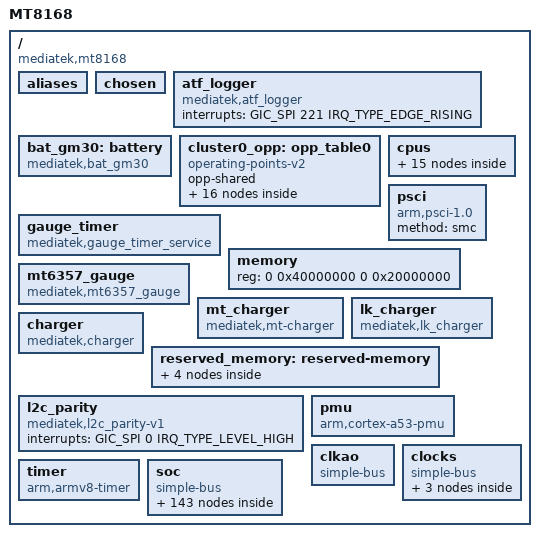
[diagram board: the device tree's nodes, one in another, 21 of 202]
/*
 * Mediatek's MT8168 SoC device tree source
 * Copyright (c) 2014-2015 MediaTek Inc.
 *
 * This program is free software; you can redistribute it and/or modify
 * it under the terms of the GNU General Public License version 2 as
 * published by the Free Software Foundation.
 *
 * This program is distributed in the hope that it will be useful,
 * MERCHANTABILITY or FITNESS FOR A PARTICULAR PURPOSE.  See the
 * GNU General Public License for more details.
 */

#include <dt-bindings/clock/mt8168-clk.h>
#include <dt-bindings/power/mt8168-power.h>
#include <dt-bindings/iio/mt635x-auxadc.h>
#include <dt-bindings/interrupt-controller/irq.h>
#include <dt-bindings/interrupt-controller/arm-gic.h>
#include <dt-bindings/reset/mt8168-resets.h>
#include <dt-bindings/memory/mt8168-larb-port.h>
#include <dt-bindings/phy/phy.h>
#include <dt-bindings/pinctrl/mt8168-pinfunc.h>
#include <dt-bindings/power/mt8168-power.h>
#include <dt-bindings/mfd/mt6357-irq.h>

/ {
	model = "MT8168";
	compatible = "mediatek,mt8168";
	interrupt-parent = <&sysirq>;
	#address-cells = <2>;
	#size-cells = <2>;

	aliases {
		ovl0 = &disp_ovl0;
		ovl_2l0 = &disp_ovl0_2l;
		rdma0 = &disp_rdma0;
		rdma1 = &disp_rdma1;
		wdma0 = &disp_wdma0;
		color0 = &disp_color0;
		ccorr0 = &disp_ccorr0;
		dsi0 = &dsi0;
		aal0 = &disp_aal0;
		gamma0 = &disp_gamma0;
		dither0 = &disp_dither0;
	};

	/* chosen */
	chosen: chosen {
		bootargs = "console=tty0 console=ttyS0,921600n1 earlycon=uart8250,mmio32,0x11002000 vmalloc=496M androidboot.hardware=mt8168 firmware_class.path=/vendor/firmware loop.max_part=7";
	};
	/* ATF logger SW IRQ number 253 = 32 + 221 */
	atf_logger {
		compatible = "mediatek,atf_logger";
		interrupts = <GIC_SPI 221 IRQ_TYPE_EDGE_RISING>;
	};

	bat_gm30: battery {
		compatible = "mediatek,bat_gm30";
	};

	cluster0_opp: opp_table0 {
		compatible = "operating-points-v2";
		opp-shared;
		opp-850000000 {
			opp-hz = /bits/ 64 <850000000>;
			opp-microvolt = <650000>;
		};
		opp-918000000 {
			opp-hz = /bits/ 64 <918000000>;
			opp-microvolt = <668750>;
		};
		opp-987000000 {
			opp-hz = /bits/ 64 <987000000>;
			opp-microvolt = <687500>;
		};
		opp-1056000000 {
			opp-hz = /bits/ 64 <1056000000>;
			opp-microvolt = <706250>;
		};
		opp-1125000000 {
			opp-hz = /bits/ 64 <1125000000>;
			opp-microvolt = <725000>;
		};
		opp-1216000000 {
			opp-hz = /bits/ 64 <1216000000>;
			opp-microvolt = <750000>;
		};
		opp-1308000000 {
			opp-hz = /bits/ 64 <1308000000>;
			opp-microvolt = <775000>;
		};
		opp-1400000000 {
			opp-hz = /bits/ 64 <1400000000>;
			opp-microvolt = <800000>;
		};
		opp-1466000000 {
			opp-hz = /bits/ 64 <1466000000>;
			opp-microvolt = <825000>;
		};
		opp-1533000000 {
			opp-hz = /bits/ 64 <1533000000>;
			opp-microvolt = <850000>;
		};
		opp-1633000000 {
			opp-hz = /bits/ 64 <1633000000>;
			opp-microvolt = <887500>;
		};
		opp-1700000000 {
			opp-hz = /bits/ 64 <1700000000>;
			opp-microvolt = <912500>;
		};
		opp-1767000000 {
			opp-hz = /bits/ 64 <1767000000>;
			opp-microvolt = <937500>;
		};
		opp-1834000000 {
			opp-hz = /bits/ 64 <1834000000>;
			opp-microvolt = <962500>;
		};
		opp-1917000000 {
			opp-hz = /bits/ 64 <1917000000>;
			opp-microvolt = <993750>;
		};
		opp-2001000000 {
			opp-hz = /bits/ 64 <2001000000>;
			opp-microvolt = <1025000>;
		};
	};

	cpus: cpus {
		#address-cells = <1>;
		#size-cells = <0>;

		cpu-map {
			cluster0: cluster0 {
				core0 {
					cpu = <&cpu0>;
				};
				core1 {
					cpu = <&cpu1>;
				};
				core2 {
					cpu = <&cpu2>;
				};
				core3 {
					cpu = <&cpu3>;
				};
			};
		};

		cpu0: cpu@0 {
			device_type = "cpu";
			compatible = "arm,cortex-a53";
			reg = <0x0>;
			clock-frequency = <1600000000>;
			enable-method = "psci";
			cpu-idle-states = <&MCDI_CPU &MCDI_CLUSTER &SODI
					   &DPIDLE>;
			clocks = <&mcusys CLK_MCU_BUS_SEL>,
				 <&apmixedsys CLK_APMIXED_MAINPLL>,
				 <&apmixedsys CLK_APMIXED_ARMPLL>;
			clock-names = "cpu", "intermediate", "armpll";
			operating-points-v2 = <&cluster0_opp>;
		};

		cpu1: cpu@1 {
			device_type = "cpu";
			compatible = "arm,cortex-a53";
			reg = <0x1>;
			clock-frequency = <1600000000>;
			enable-method = "psci";
			cpu-idle-states = <&MCDI_CPU &MCDI_CLUSTER &SODI
					   &DPIDLE>;
			clocks = <&mcusys CLK_MCU_BUS_SEL>,
				 <&apmixedsys CLK_APMIXED_MAINPLL>,
				 <&apmixedsys CLK_APMIXED_ARMPLL>;
			clock-names = "cpu", "intermediate", "armpll";
			operating-points-v2 = <&cluster0_opp>;
		};

		cpu2: cpu@2 {
			device_type = "cpu";
			compatible = "arm,cortex-a53";
			reg = <0x2>;
			clock-frequency = <1600000000>;
			enable-method = "psci";
			cpu-idle-states = <&MCDI_CPU &MCDI_CLUSTER &SODI
					   &DPIDLE>;
			clocks = <&mcusys CLK_MCU_BUS_SEL>,
				 <&apmixedsys CLK_APMIXED_MAINPLL>,
				 <&apmixedsys CLK_APMIXED_ARMPLL>;
			clock-names = "cpu", "intermediate", "armpll";
			operating-points-v2 = <&cluster0_opp>;
		};

		cpu3: cpu@3 {
			device_type = "cpu";
			compatible = "arm,cortex-a53";
			reg = <0x3>;
			clock-frequency = <1600000000>;
			enable-method = "psci";
			cpu-idle-states = <&MCDI_CPU &MCDI_CLUSTER &SODI
					   &DPIDLE>;
			clocks = <&mcusys CLK_MCU_BUS_SEL>,
				 <&apmixedsys CLK_APMIXED_MAINPLL>,
				 <&apmixedsys CLK_APMIXED_ARMPLL>;
			clock-names = "cpu", "intermediate", "armpll";
			operating-points-v2 = <&cluster0_opp>;
		};

		idle-states {
			entry-method = "psci";

			MCDI_CPU: mcdi-cpu {
				compatible = "arm,idle-state";
				local-timer-stop;
				arm,psci-suspend-param = <0x00010001>;
				entry-latency-us = <300>;
				exit-latency-us = <200>;
				min-residency-us = <1000>;
			};

			MCDI_CLUSTER: mcdi-cluster {
				compatible = "arm,idle-state";
				local-timer-stop;
				arm,psci-suspend-param = <0x01010001>;
				entry-latency-us = <350>;
				exit-latency-us = <250>;
				min-residency-us = <1200>;
			};

			SODI: sodi {
				compatible = "arm,idle-state";
				local-timer-stop;
				arm,psci-suspend-param = <0x01010002>;
				entry-latency-us = <300>;
				exit-latency-us = <850>;
				min-residency-us = <2300>;
			};

			DPIDLE: dpidle {
				compatible = "arm,idle-state";
				local-timer-stop;
				arm,psci-suspend-param = <0x01010004>;
				entry-latency-us = <350>;
				exit-latency-us = <1050>;
				min-residency-us = <2800>;
			};
		};
	};

	gauge_timer {
		compatible = "mediatek,gauge_timer_service";
	};

	psci {
		compatible      = "arm,psci-1.0";
		method          = "smc";
	};

	memory {
		device_type = "memory";
		reg = <0 0x40000000 0 0x20000000>;
	};

	mt6357_gauge {
		compatible = "mediatek,mt6357_gauge";
		gauge_name = "gauge";
		alias_name = "MT6357";
	};

	mt_charger: mt_charger {
		compatible = "mediatek,mt-charger";
	};

	lk_charger: lk_charger {
		compatible = "mediatek,lk_charger";
		enable_anime;
		enable_pe_plus;
		power_path_support;
		max_charger_voltage = <6500000>;
		fast_charge_voltage = <3000000>;

		/* charging current */
		usb_charger_current = <500000>;
		ac_charger_current = <2050000>;
		ac_charger_input_current = <3200000>;
		non_std_ac_charger_current = <500000>;
		charging_host_charger_current = <1500000>;
		ta_ac_charger_current = <3000000>;
		pd_charger_current = <500000>;

		/* battery temperature protection */
		temp_t4_threshold = <50>;
		temp_t3_threshold = <45>;
		temp_t1_threshold = <0>;
	};

	charger: charger {
		compatible = "mediatek,charger";
		algorithm_name = "SwitchCharging";
		/* enable_sw_jeita; */
		enable_pe_plus;
		enable_type_c;
		power_path_support;

		/* common */
		battery_cv = <4200000>;
		max_charger_voltage = <6500000>;
		min_charger_voltage = <4600000>;

		/* charging current */
		usb_charger_current_suspend = <0>;
		usb_charger_current_unconfigured = <70000>;
		usb_charger_current_configured = <500000>;
		usb_charger_current = <500000>;
		ac_charger_current = <2050000>;
		ac_charger_input_current = <3200000>;
		non_std_ac_charger_current = <500000>;
		charging_host_charger_current = <1500000>;
		apple_1_0a_charger_current = <650000>;
		apple_2_1a_charger_current = <800000>;
		ta_ac_charger_current = <3000000>;

		/* sw jeita */
		jeita_temp_above_t4_cv = <4240000>;
		jeita_temp_t3_to_t4_cv = <4240000>;
		jeita_temp_t2_to_t3_cv = <4340000>;
		jeita_temp_t1_to_t2_cv = <4240000>;
		jeita_temp_t0_to_t1_cv = <4040000>;
		jeita_temp_below_t0_cv = <4040000>;
		temp_t4_thres = <50>;
		temp_t4_thres_minus_x_degree = <47>;
		temp_t3_thres = <45>;
		temp_t3_thres_minus_x_degree = <39>;
		temp_t2_thres = <10>;
		temp_t2_thres_plus_x_degree = <16>;
		temp_t1_thres = <0>;
		temp_t1_thres_plus_x_degree = <6>;
		temp_t0_thres = <0>;
		temp_t0_thres_plus_x_degree = <0>;
		temp_neg_10_thres = <0>;

		/* battery temperature protection */
		enable_min_charge_temp;
		min_charge_temp = <0>;
		min_charge_temp_plus_x_degree = <6>;
		max_charge_temp = <50>;
		max_charge_temp_minus_x_degree = <47>;

		/* PE */
		ta_12v_support;
		ta_9v_support;
		pe_ichg_level_threshold = <1000000>; /* uA */
		ta_ac_12v_input_current = <3200000>;
		ta_ac_9v_input_current = <3200000>;
		ta_ac_7v_input_current = <3200000>;

		/* cable measurement impedance */
		cable_imp_threshold = <699>;
		vbat_cable_imp_threshold = <3900000>; /* uV */

		/* bif */
		bif_threshold1 = <4250000>;
		bif_threshold2 = <4300000>;
		bif_cv_under_threshold2 = <4450000>;
	};

	reserved_memory: reserved-memory {
		#address-cells = <2>;
		#size-cells = <2>;
		ranges;

		adsp_reserved: adsp-reserved-memory@50000000 {
			compatible = "mediatek,adsp-reserved-memory";
			no-map;
			reg = <0 0x50000000 0 0x1800000>;
		};

		atf_reserved_memory: atf-reserved-memory {
			compatible = "mediatek,mt8168-atf-reserved-memory";
			no-map;
			reg = <0 0x54600000 0 0x30000>;
		};

		consys-reserve-memory {
			compatible = "mediatek,consys-reserve-memory";
			no-map;
			size = <0 0x400000>;
			alignment = <0 0x1000000>;
			alloc-ranges = <0 0x40000000 0 0x80000000>;
		};

		wifi-reserve-memory {
			compatible = "mediatek,wifi-reserve-memory";
			no-map;
			size = <0 0x300000>;
			alignment = <0 0x1000000>;
			alloc-ranges = <0 0x40000000 0 0x80000000>;
		};
	};

	l2c_parity {
		compatible = "mediatek,l2c_parity-v1";
		interrupts = <GIC_SPI 0 IRQ_TYPE_LEVEL_HIGH>;
	};

	pmu {
		compatible = "arm,cortex-a53-pmu",
			     "arm,cortex-a7-pmu";
		interrupt-parent = <&gic>;
		interrupts = <GIC_PPI 7 IRQ_TYPE_LEVEL_LOW>;
	};

	clkao: clkao {
		compatible = "simple-bus";
	};

	clocks {
		#address-cells = <2>;
		#size-cells = <2>;
		compatible = "simple-bus";
		ranges;

		clk26m: clk26m {
			compatible = "fixed-clock";
			#clock-cells = <0>;
			clock-frequency = <26000000>;
		};

		clk32k: clk32k {
			compatible = "fixed-clock";
			#clock-cells = <0>;
			clock-frequency = <32000>;
		};

		uart_clk: dummy26m {
			compatible = "fixed-clock";
			clock-frequency = <26000000>;
			#clock-cells = <0>;
		};
	};

	timer: timer {
		compatible = "arm,armv8-timer";
		interrupt-parent = <&gic>;
		interrupts = <GIC_PPI 13
			     (GIC_CPU_MASK_SIMPLE(4) | IRQ_TYPE_LEVEL_LOW)>,
			     <GIC_PPI 14
			     (GIC_CPU_MASK_SIMPLE(4) | IRQ_TYPE_LEVEL_LOW)>,
			     <GIC_PPI 11
			     (GIC_CPU_MASK_SIMPLE(4) | IRQ_TYPE_LEVEL_LOW)>,
			     <GIC_PPI 10
			     (GIC_CPU_MASK_SIMPLE(4) | IRQ_TYPE_LEVEL_LOW)>;
		clock-frequency = <13000000>;
	};

	soc {
		#address-cells = <2>;
		#size-cells = <2>;
		compatible = "simple-bus";
		ranges;

		chipid: chipid@08000000 {
			compatible = "mediatek,chipid";
			reg = <0 0x08000000 0 0x0004>,
			      <0 0x08000004 0 0x0004>,
			      <0 0x08000008 0 0x0004>,
			      <0 0x0800000c 0 0x0004>;
		};

		gic: interrupt-controller@c000000 {
			compatible = "arm,gic-v3";
			interrupt-controller;
			#interrupt-cells = <3>;
			#address-cells = <2>;
			#size-cells = <2>;
			#redistributor-regions = <1>;
			interrupt-parent = <&gic>;
			reg = <0 0xc000000 0 0x80000>,
			      <0 0xc080000 0 0x80000>;
			interrupts = <GIC_PPI 9
				(GIC_CPU_MASK_SIMPLE(4) | IRQ_TYPE_LEVEL_HIGH)>;
		};

		topckgen: topckgen@10000000 {
			compatible = "mediatek,mt8168-topckgen", "syscon";
			reg = <0 0x10000000 0 0x1000>;
			#clock-cells = <1>;
		};

		infracfg: infracfg@10001000 {
			compatible = "mediatek,mt8168-infracfg", "syscon";
			reg = <0 0x10001000 0 0x1000>;
			#clock-cells = <1>;
		};

		syscfg_pctl_a: syscfg_pctl_a@10005000 {
			compatible = "mediatek,pctl-a-syscfg", "syscon";
			reg = <0 0x10005000 0 0x1000>;
		};

		scpsys: syscon@10006000 {
			compatible = "mediatek,mt8168-scpsys", "syscon";
			#power-domain-cells = <1>;
			reg = <0 0x10006000 0 0x1000>;
			clocks = <&topckgen CLK_TOP_AUD_INTBUS_SEL>,
				 <&infracfg CLK_IFR_AUDIO>,
				 <&infracfg CLK_IFR_AUD_26M_BK>,
				 <&topckgen CLK_TOP_MFG_SEL>,
				 <&topckgen CLK_TOP_MM_SEL>,
				 <&topckgen CLK_TOP_DSP_SEL>,
				 <&topckgen CLK_TOP_DSP_26M>,
				 <&mmsys CLK_MM_MM_SMI_COMMON>,
				 <&mmsys CLK_MM_MM_SMI_COMM0>,
				 <&mmsys CLK_MM_MM_SMI_COMM1>,
				 <&mmsys CLK_MM_MM_SMI_LARB0>,
				 <&camsys CLK_CAM_LARB2>,
				 <&camsys CLK_CAM_SENIF>,
				 <&camsys CLK_CAMSV0>,
				 <&camsys CLK_CAMSV1>,
				 <&camsys CLK_CAM_FDVT>,
				 <&camsys CLK_CAM_WPE>,
				 <&infracfg CLK_IFR_APU_AXI>,
				 <&apu CLK_APU_IPU_CK>,
				 <&apu CLK_APU_AXI>,
				 <&apu CLK_APU_JTAG>,
				 <&apu CLK_APU_IF_CK>,
				 <&apu CLK_APU_EDMA>,
				 <&apu CLK_APU_AHB>,
				 <&topckgen CLK_TOP_CONN_32K>,
				 <&topckgen CLK_TOP_CONN_26M>;
			clock-names = "audio", "audio1", "audio2",
				      "mfg", "mm", "dsp", "dsp1",
				      "mm-0", "mm-1", "mm-2",
				      "mm-3", "cam-0","cam-1",
				      "cam-2", "cam-3", "cam-4",
				      "cam-5", "apu", "apu-1",
				      "apu-2", "apu-3", "apu-4",
				      "apu-5", "apu-6", "conn",
				      "conn1";
			infracfg = <&infracfg>;
			smi_comm = <&smi_common>;
			infracfg_nao = <&infracfg_nao>;
			conn-supply = <&mt_pmic_vcn28_ldo_reg>;
		};

		toprgu: toprgu@10007000 {
			compatible = "mediatek,mt8168-rgu",
				     "mediatek,mt6589-wdt";
			reg = <0 0x10007000 0 0x1000>;
			interrupts = <GIC_SPI 83 IRQ_TYPE_EDGE_FALLING>;
			#reset-cells = <1>;
		};

		gpt: apxgpt@10008000 {
			compatible = "mediatek,mt8168-timer",
				     "mediatek,mt6577-timer";
			reg = <0 0x10008000 0 0x1000>;
			interrupts = <GIC_SPI 114 IRQ_TYPE_LEVEL_LOW>;
			clocks = <&topckgen CLK_TOP_SYS_26M_D2>;
			clock-names = "clk13m";
		};

		pio: pinctrl@1000b000 {
			compatible = "mediatek,mt8168-pinctrl";
			reg = <0 0x1000b000 0 0x1000>;
			mediatek,pctl-regmap = <&syscfg_pctl_a>;
			pins-are-numbered;
			gpio-controller;
			#gpio-cells = <2>;
			interrupt-controller;
			#interrupt-cells = <2>;
			interrupts = <GIC_SPI 115 IRQ_TYPE_LEVEL_HIGH>;
		};

		apmixedsys: syscon@1000c000 {
			compatible = "mediatek,mt8168-apmixedsys", "syscon";
			reg = <0 0x1000c000 0 0x1000>;
			#clock-cells = <1>;
		};

		fhctl: fhctl@1000ce00 {
			compatible = "mediatek,fhctl";
			reg = <0 0x1000ce00 0 0x200>;
		};

		pwrap: pwrap@1000d000 {
			compatible = "mediatek,mt8168-pwrap";
			reg = <0 0x1000d000 0 0x1000>;
			reg-names = "pwrap";
			interrupts = <GIC_SPI 123 IRQ_TYPE_LEVEL_HIGH>;
			clocks = <&infracfg CLK_IFR_PWRAP_SPI>,
				<&infracfg CLK_IFR_PMIC_AP>,
				<&infracfg CLK_IFR_PWRAP_SYS>,
				<&infracfg CLK_IFR_PWRAP_TMR>;
			clock-names = "spi", "wrap", "wrap_sys", "wrap_tmr";

			main_pmic: mt6357-pmic {
				interrupt-parent = <&pio>;
				interrupts = <145 IRQ_TYPE_LEVEL_HIGH>;
				status = "okay";
			};
		};

		pwraph: pwraphal@ {
			compatible = "mediatek,pwraph";
			mediatek,pwrap-regmap = <&pwrap>;
		};

		keypad: keypad@10010000 {
			compatible = "mediatek,kp";
			reg = <0 0x10010000 0 0x1000>;
			interrupts = <GIC_SPI 124 IRQ_TYPE_EDGE_FALLING>;
		};

		dvfsrc@10012000 {
			compatible = "mediatek,dvfsrc";
			reg = <0 0x10012000 0 0x1000>,
			      <0 0x00110780 0 0x80>,
			      <0 0x10006000 0 0x1000>;
			clocks = <&infracfg CLK_IFR_DVFSRC>;
			clock-names = "dvfsrc";
		};

		irrx: irrx@1001F000 {
			compatible = "mediatek,mt8168-irrx";
			reg = <0 0x1001F000 0 0x1000>;
			interrupts = <GIC_SPI 142 IRQ_TYPE_LEVEL_LOW>;
			clocks = <&infracfg CLK_IFR_IRRX_32K>,
				 <&infracfg CLK_IFR_IRRX_26M>;
			clock-names = "irrx_clock", "irrx_sw_clock";
			status = "disabled";
		};

		mcusys: mcusys@10200000 {
			compatible = "mediatek,mt8168-mcusys",
				     "mediatek,mt8168-mcucfg", "syscon";
			reg = <0 0x10200000 0 0x2000>;
			interrupts = <GIC_SPI 0 IRQ_TYPE_LEVEL_HIGH>;
			#clock-cells = <1>;
		};

		sysirq: intpol-controller@10200a80 {
			compatible = "mediatek,mt8168-sysirq",
				     "mediatek,mt6577-sysirq";
			interrupt-controller;
			#interrupt-cells = <3>;
			interrupt-parent = <&gic>;
			reg = <0 0x10200a80 0 0x20>;
		};

		dfd: dfd@10200b00 {
			compatible = "mediatek,dfd";
			reg = <0 0x10200b00 0 0x10000>;
			mediatek,enabled = <1>;
			mediatek,chain_length = <0x61a8>;
			mediatek,rg_dfd_timeout = <0xa0>;
		};

		sys_cirq: sys_cirq@10202000 {
			compatible = "mediatek,mt8168-sys_cirq",
				     "mediatek,mt6735-sys_cirq",
				     "mediatek,sys_cirq";
			reg = <0 0x10202000 0 0x1000>;
			interrupts = <GIC_SPI 218 IRQ_TYPE_LEVEL_LOW>;
			mediatek,cirq_num = <147>;
			mediatek,spi_start_offset = <72>;
		};

		systracker: systracker@10208000 {
			compatible = "mediatek,bus_dbg-v2";
			reg = <0 0x10208000 0 0x1000>,
			      <0 0x10001000 0 0x1000>;
			mediatek,bus_dbg_con_offset = <0x2fc>;
			interrupts = <GIC_SPI 85 IRQ_TYPE_LEVEL_LOW>;
		};

		rng: rng@1020f000 {
			compatible = "mediatek,mt8168-rng",
				     "mediatek,mt7623-rng";
			reg = <0 0x1020f000 0 0x100>;
			clocks = <&infracfg CLK_IFR_TRNG>;
			clock-names = "rng";
		};

		apdma: dma-controller@11000280 {
			compatible = "mediatek,mt8168-uart-dma",
				     "mediatek,mt6577-uart-dma";
			reg = <0 0x11000280 0 0x80>,
			      <0 0x11000300 0 0x80>,
			      <0 0x11000380 0 0x80>,
			      <0 0x11000400 0 0x80>;
			interrupts = <GIC_SPI 45 IRQ_TYPE_LEVEL_LOW>,
				     <GIC_SPI 46 IRQ_TYPE_LEVEL_LOW>,
				     <GIC_SPI 47 IRQ_TYPE_LEVEL_LOW>,
				     <GIC_SPI 48 IRQ_TYPE_LEVEL_LOW>;
			dma-requests = <4>;
			clocks = <&infracfg CLK_IFR_AP_DMA>;
			clock-names = "apdma";
			#dma-cells = <1>;
		};

		spi: spi@1100a000 {
			compatible = "mediatek,mt8168-spi";
			#address-cells = <1>;
			#size-cells = <0>;
			reg = <0 0x1100a000 0 0x100>;
			interrupts = <GIC_SPI 62 IRQ_TYPE_LEVEL_LOW>;
			clocks = <&topckgen CLK_TOP_UNIVPLL2_D4>,
				 <&topckgen CLK_TOP_SPI_SEL>,
				 <&infracfg CLK_IFR_SPI0>;
			clock-names = "parent-clk", "sel-clk", "spi-clk";
			status = "disabled";
		};

		svs: svs@1100b000 {
			compatible = "mediatek,mt8168-svs";
			reg = <0 0x1100b000 0 0x1000>;
			interrupts = <GIC_SPI 69 IRQ_TYPE_LEVEL_LOW>;
			clocks = <&infracfg CLK_IFR_THERM>;
			clock-names = "main_clk";
			nvmem-cells = <&svs_calibration>;
			nvmem-cell-names = "svs-calibration-data";

			svs_cpu_little: svs_cpu_little {
				compatible = "mediatek,mt8168-svs-cpu-little";
				operating-points-v2 = <&cluster0_opp>;
			};
		};

		iommu: m4u@10205000 {
			compatible = "mediatek,mt8168-m4u";
			reg = <0 0x10205000 0 0x1000>;
			mediatek,larbs = <&larb0 &larb1 &larb2 &larb3>;
			interrupts = <GIC_SPI 102 IRQ_TYPE_LEVEL_LOW>;
			#iommu-cells = <1>;
		};

		infracfg_nao: infracfg_nao@1020e000 {
			compatible = "syscon";
			reg = <0 0x1020e000 0 0x1000>;
		};

		emi: emi@10219000 {
			compatible = "mediatek,mt8168-emi";
			reg = <0 0x10219000 0 0x1000>,
			      <0 0x10226000 0 0x1000>,
			      <0 0x1022f000 0 0x1000>,
			      <0 0x10239000 0 0x1000>;
			interrupts = <GIC_SPI 88 IRQ_TYPE_LEVEL_LOW>;
		};

		dramc: dramc@1022c000 {
			compatible = "mediatek,dramc";
			reg = <0 0x1022c000 0 0x2000>, /* DRAMC AO CHA */
			      <0 0x10232000 0 0x2000>, /* DRAMC AO CHB */
			      <0 0x1022e000 0 0x1000>, /* DRAMC NAO CHA */
			      <0 0x10238000 0 0x1000>, /* DRAMC NAO CHB */
			      <0 0x10228000 0 0x2000>, /* DDRPHY AO CHA */
			      <0 0x10234000 0 0x2000>, /* DDRPHY AO CHB */
			      <0 0x10230000 0 0x1000>, /* DDRPHY NAO CHA */
			      <0 0x1023a000 0 0x1000>, /* DDRPHY NAO CHB */
			      <0 0x10017000 0 0x1000>, /* sys timer */
			      <0 0x10006000 0 0x1000>; /* SPM */
		};

		gce: gce@1023c000 {
			compatible = "mediatek,gce", "syscon";
			reg = <0 0x1023c000 0 0x4000>;
			mediatek,larb = <&larb0>;
			power-domains = <&scpsys MT8168_POWER_DOMAIN_DISP>;
			#clock-cells = <1>;
			interrupts = <GIC_SPI 98 IRQ_TYPE_LEVEL_LOW>,
				     <GIC_SPI 99 IRQ_TYPE_LEVEL_LOW>;
			g3d_config_base = <0x13000000 0 0xffff0000>;
			mmsys_config_base = <0x14000000 1 0xffff0000>;
			disp_dither_base = <0x14010000 2 0xffff0000>;
			mm_na_base = <0x14020000 3 0xffff0000>;
			vdec_base = <0x16000000 30 0xffff0000>;
			vdec1_base = <0x16020000 31 0xffff0000>;
			camsys_base = <0x15000000 22 0xffff0000>;
			infracfg_ao_base = <0x10000000 10 0xffff0000>;
			devapc_ao_mm_base = <0x10010000 11 0xffff0000>;
			mdp_rdma0_sof = <0>;
			mdp_ccorr0_sof = <1>;
			mdp_rsz0_sof = <2>;
			mdp_rsz1_sof = <3>;
			mdp_wrot1_sof = <4>;
			mdp_wrot0_sof = <5>;
			mdp_tdshp0_sof = <6>;
			disp_ovl0_sof = <7>;
			disp_2l_ovl0_sof = <8>;
			disp_rdma0_sof = <9>;
			disp_rdma1_sof = <10>;
			disp_wdma0_sof = <11>;
			disp_color0_sof = <12>;
			disp_ccorr0_sof = <13>;
			disp_aal0_sof = <14>;
			disp_gamma0_sof = <15>;
			disp_dither0_sof = <16>;
			disp_dsi0_sof = <17>;
			img_dl_relay_sof = <18>;
			disp_rsz0_sof = <19>;
			disp_pwm0_sof = <20>;
			mdp_rdma1_sof = <21>;
			disp_dpi0_sof = <22>;
			mdp_rdma0_frame_done = <23>;
			mdp_ccorr0_frame_done = <24>;
			mdp_rsz0_frame_done = <25>;
			mdp_rsz1_frame_done = <26>;
			mdp_wrot0_write_frame_done = <27>;
			mdp_wrot1_write_frame_done = <28>;
			mdp_tdshp0_frame_done = <29>;
			disp_ovl0_frame_done = <30>;
			disp_2l_ovl0_frame_done = <31>;
			disp_rsz0_frame_done = <32>;
			disp_rdma0_frame_done = <33>;
			disp_rdma1_frame_done = <34>;
			disp_wdma0_frame_done = <35>;
			disp_color0_frame_done = <36>;
			disp_ccorr0_frame_done = <37>;
			disp_aal0_frame_done = <38>;
			disp_gamma0_frame_done = <39>;
			disp_dither0_frame_done = <40>;
			disp_dsi0_frame_done = <41>;
			mdp_rdma1_frame_done = <42>;
			disp_dpi0_frame_done = <43>;
			reserved1_frame_done = <44>;
			reserved0_frame_done = <45>;
			stream_done_0 = <130>;
			stream_done_1 = <131>;
			stream_done_2 = <132>;
			stream_done_3 = <133>;
			stream_done_4 = <134>;
			stream_done_5 = <135>;
			stream_done_6 = <136>;
			stream_done_7 = <137>;
			stream_done_8 = <138>;
			stream_done_9 = <139>;
			buf_underrun_event_0 = <140>;
			buf_underrun_event_1 = <141>;
			dsi0_te_pulse = <142>;
			dsi0_irq_event = <143>;
			dsi0_done_event = <144>;
			disp_wdma0_rst_done = <148>;
			mdp_wrot1_rst_done = <149>;
			mdp_wrot0_rst_done = <150>;
			mdp_rdma1_rst_done = <151>;
			mdp_rdma0_rst_done = <152>;
			disp_ovl0_frame_rst_done_pusle = <153>;
			isp_frame_done_p2_2 = <257>;
			isp_frame_done_p2_1 = <258>;
			isp_frame_done_p2_0 = <259>;
			isp_frame_done_p1_1 = <260>;
			isp_frame_done_p1_0 = <261>;
			camsv_0_pass1_done = <262>;
			camsv_1_pass1_done = <263>;
			seninf_cam0_fifo_full = <264>;
			seninf_cam1_fifo_full = <265>;
			seninf_cam2_fifo_full = <266>;
			seninf_cam3_fifo_full = <267>;
			seninf_cam4_fifo_full = <268>;
			seninf_cam5_fifo_full = <269>;
			seninf_cam6_fifo_full = <270>;
			seninf_cam7_fifo_full = <271>;
			fdvt_done = <272>;
			wpe_gce_frame_done = <273>;
			JPGENC_CMDQ_PAUSE_DONE = <289>;
			jpgenc_done = <290>;
			venc_cmdq_pause_done = <291>;
			venc_done = <292>;
			venc_mb_done = <293>;
			venc_128byte_cnt_done = <294>;
			out_event_0 = <898>;
			apu_gce_core0_event_0 = <321>;
			apu_gce_core0_event_1 = <322>;
			apu_gce_core0_event_2 = <323>;
			apu_gce_core0_event_3 = <324>;
			vdec_sof = <352>;
			vdec_frame_done_0 = <353>;
			vdec_frame_done_1 = <354>;
			vdec_frame_done_2 = <355>;
			vdec_frame_done_3 = <356>;
			vdec_frame_done_4 = <357>;
			vdec_frame_done_5 = <358>;
			vdec_frame_done_6 = <359>;
			vdec_event_0 = <360>;
			vdec_event_1 = <361>;
			vdec_event_2 = <362>;
			vdec_event_3 = <363>;
			vdec_event_4 = <364>;
			vdec_event_5 = <365>;
			vdec_event_6 = <366>;
			vdec_event_7 = <367>;
			max_prefetch_cnt = <1>;
			prefetch_size = <96>;
			sram_size_cpr_64 = <64>;
			mmsys_config = <&mmsys_config>;
			mdp_rdma0 = <&mdp_rdma0>;
			mdp_rdma1 = <&mdp_rdma1>;
			mdp_rsz0 = <&mdp_rsz0>;
			mdp_rsz1 = <&mdp_rsz1>;
			mdp_wrot0 = <&mdp_wrot0>;
			mdp_wrot1 = <&mdp_wrot1>;
			mdp_tdshp0 = <&mdp_tdshp0>;
			mdp_color0 = <&disp_color0>;
			mdp_ccorr0 = <&mdp_ccorr>;
			mm_mutex = <&disp_mutex0>;
			sram_share_cnt = <1>;
			sram_share_engine = <10>;
			sram_share_event = <710>;
			clocks = <&infracfg CLK_IFR_GCE>,
				 <&infracfg CLK_IFR_GCE_26M>;
			clock-names = "GCE", "GCE_TIMER";
			mediatek,mailbox-gce = <&gce_mbox>;
			mboxes = <&gce_mbox 0 0 4>,
				<&gce_mbox 1 0 4>,
				<&gce_mbox 2 0 5>,
				<&gce_mbox 3 0 4>,
				<&gce_mbox 4 0 4>,
				<&gce_mbox 5 0xffffffff 2>,
				<&gce_mbox 6 200 4>,
				<&gce_mbox 7 0xffffffff 2>,
				<&gce_mbox_svp 8 0 1>,
				<&gce_mbox_svp 9 0 4>,
				<&gce_mbox_svp 10 0 4>,
				<&gce_mbox 11 0 1>,
				<&gce_mbox 12 0 1>,
				<&gce_mbox 13 0 1>,
				<&gce_mbox 14 0 1>,
				<&gce_mbox 15 0xffffffff 1>;
		};

		gce_mbox: gce_mbox@1023c000 {
			compatible = "mediatek,mailbox-gce";
			reg = <0 0x1023c000 0 0x4000>;
			interrupts = <GIC_SPI 98 IRQ_TYPE_LEVEL_LOW>;
			#mbox-cells = <3>;
			#gce-event-cells = <1>;
			#gce-subsys-cells = <2>;
			clocks = <&infracfg CLK_IFR_GCE>,
				 <&infracfg CLK_IFR_GCE_26M>;
			clock-names = "gce", "GCE_TIMER";
		};

		gce_mbox_svp: gce_mbox_svp@1023c000 {
			compatible = "mediatek,mailbox-gce-svp";
			reg = <0 0x1023c000 0 0x4000>;
			interrupts = <GIC_SPI 98 IRQ_TYPE_LEVEL_LOW>;
			#mbox-cells = <3>;
			clocks = <&infracfg CLK_IFR_GCE>,
				 <&infracfg CLK_IFR_GCE_26M>;
			clock-names = "gce", "GCE_TIMER";
		};

		auxadc: adc@11001000 {
			compatible = "mediatek,mt8168-auxadc",
				     "mediatek,mt2701-auxadc";
			reg = <0 0x11001000 0 0x1000>;
			clocks = <&infracfg CLK_IFR_AUXADC>;
			clock-names = "main";
			#io-channel-cells = <1>;
			status = "disabled";
		};

		uart0: uart0@11002000 {
			compatible = "mediatek,mt8168-uart",
				     "mediatek,mt6577-uart";
			reg = <0 0x11002000 0 0x1000>;
			interrupts = <GIC_SPI 35 IRQ_TYPE_LEVEL_LOW>;
			clocks = <&clk26m>, <&infracfg CLK_IFR_UART0>;
			clock-names = "baud", "bus";
			dmas = <&apdma 0
				&apdma 1>;
			dma-names = "tx", "rx";
			status = "disabled";
		};

		uart1: uart1@11003000 {
			compatible = "mediatek,mt8168-uart",
				     "mediatek,mt6577-uart";
			reg = <0 0x11003000 0 0x1000>;
			interrupts = <GIC_SPI 36 IRQ_TYPE_LEVEL_LOW>;
			clocks = <&clk26m>, <&infracfg CLK_IFR_UART1>;
			clock-names = "baud", "bus";
			dmas = <&apdma 2
				&apdma 3>;
			dma-names = "tx", "rx";
			status = "disabled";
		};

		pwm: pwm@11006000 {
			compatible = "mediatek,mt8168-pwm";
			reg = <0 0x11006000 0 0x1000>;
			interrupts = <GIC_SPI 76 IRQ_TYPE_LEVEL_LOW>;
			clocks = <&infracfg CLK_IFR_PWM_HCLK>,
				 <&infracfg CLK_IFR_PWM>,
				 <&infracfg CLK_IFR_PWM1>,
				 <&infracfg CLK_IFR_PWM2>,
				 <&infracfg CLK_IFR_PWM3>;
			clock-names = "top", "main", "pwm1", "pwm2", "pwm3";
		};

		i2c0: i2c@11007000 {
			compatible = "mediatek,mt8168-i2c",
				     "mediatek,mt2712-i2c";
			reg = <0 0x11007000 0 0xa0>,
			      <0 0x11000080 0 0x80>;
			interrupts = <GIC_SPI 28 IRQ_TYPE_LEVEL_LOW>;
			clock-div = <1>;
			clocks = <&infracfg CLK_IFR_I2C0_AXI>,
				 <&infracfg CLK_IFR_AP_DMA>;
			clock-names = "main", "dma";
			#address-cells = <1>;
			#size-cells = <0>;
			status = "disabled";
		};

		i2c1: i2c@11008000 {
			compatible = "mediatek,mt8168-i2c",
				     "mediatek,mt2712-i2c";
			reg = <0 0x11008000 0 0xa0>,
			      <0 0x11000100 0 0x80>;
			interrupts = <GIC_SPI 29 IRQ_TYPE_LEVEL_LOW>;
			clock-div = <1>;
			clocks = <&infracfg CLK_IFR_I2C1_AXI>,
				 <&infracfg CLK_IFR_AP_DMA>;
			clock-names = "main", "dma";
			#address-cells = <1>;
			#size-cells = <0>;
			status = "disabled";
		};

		i2c2: i2c@11009000 {
			compatible = "mediatek,mt8168-i2c",
				     "mediatek,mt2712-i2c";
			reg = <0 0x11009000 0 0xa0>,
			      <0 0x11000180 0 0x80>;
			interrupts = <GIC_SPI 30 IRQ_TYPE_LEVEL_LOW>;
			clock-div = <1>;
			clocks = <&infracfg CLK_IFR_I2C2_AXI>,
				 <&infracfg CLK_IFR_AP_DMA>;
			clock-names = "main", "dma";
			#address-cells = <1>;
			#size-cells = <0>;
			status = "disabled";
		};

		therm_ctrl@1100b000 {
			compatible = "mediatek,therm_ctrl";
			reg = <0 0x1100b000 0 0x1000>;
			interrupts = <GIC_SPI 22 IRQ_TYPE_LEVEL_LOW>;
			clocks = <&infracfg CLK_IFR_THERM>;
			clock-names = "therm-main";
			mediatek,auxadc = <&auxadc 0>;
			mediatek,apmixed = <&apmixedsys>;
			mediatek,infracfg_ao = <&infracfg>;
		};

		tboard_thermistor: thermal-sensor {
			compatible = "generic-adc-thermal";
			#thermal-sensor-cells = <0>;
			io-channels = <&auxadc 0>;
			io-channel-names = "sensor-channel";
		};

		btif@1100c000 {
			compatible = "mediatek,btif";
				/*btif base*/
			reg = <0 0x1100c000 0 0x1000>,
				/*btif tx dma base*/
				<0 0x11000480 0 0x80>,
				/*btif rx dma base*/
				<0 0x11000500 0 0x80>;
				/*btif irq, IRQS_Sync ID, btif_irq_b*/
			interrupts = <GIC_SPI 56 IRQ_TYPE_LEVEL_LOW>,
				/*btif tx dma irq*/
				<GIC_SPI 49 IRQ_TYPE_LEVEL_LOW>,
				/*btif rx dma irq*/
				<GIC_SPI 50 IRQ_TYPE_LEVEL_LOW>;
			clocks = <&infracfg CLK_IFR_BTIF>,
				/*btif clock*/
				<&infracfg CLK_IFR_AP_DMA>;
				/*ap dma clock*/
			clock-names = "btifc","apdmac";
		};

		disp_pwm0: disp_pwm@1100e000 {
			compatible = "mediatek,disp_pwm",
				     "mediatek,mt8183-disp-pwm";
			reg = <0 0x1100e000 0 0x1000>;
			#pwm-cells = <2>;
			clocks = <&topckgen CLK_TOP_DISP_PWM_SEL>,
				 <&infracfg CLK_IFR_DISP_PWM>;
			clock-names = "main", "mm";
		};

		i2c3: i2c@1100f000 {
			compatible = "mediatek,mt8168-i2c",
				     "mediatek,mt2712-i2c";
			reg = <0 0x1100f000 0 0xa0>,
			      <0 0x11000200 0 0x80>;
			interrupts = <GIC_SPI 31 IRQ_TYPE_LEVEL_LOW>;
			clock-div = <1>;
			clocks = <&infracfg CLK_IFR_I2C3_AXI>,
				 <&infracfg CLK_IFR_AP_DMA>;
			clock-names = "main", "dma";
			#address-cells = <1>;
			#size-cells = <0>;
			status = "disabled";
		};

		nandc: nfi@11018000 {
			compatible = "mediatek,mt8168-nfc";
			reg = <0 0x11018000 0 0x1000>;
			interrupts = <GIC_SPI 78 IRQ_TYPE_LEVEL_LOW>;
			clocks = <&infracfg CLK_IFR_NFI1X_BK>,
				 <&infracfg CLK_IFR_NFI_BK>;
			clock-names = "nfi_clk", "pad_clk";
			ecc-engine = <&bch>;
			#address-cells = <1>;
			#size-cells = <0>;
			status = "disabled";
		};

		bch: ecc@11019000 {
			compatible = "mediatek,mt8168-ecc";
			reg = <0 0x11019000 0 0x1000>;
			interrupts = <GIC_SPI 79 IRQ_TYPE_LEVEL_LOW>;
			clocks = <&infracfg CLK_IFR_NFIECC_BK>;
			clock-names = "nfiecc_clk";
			status = "disabled";
		};

		ssusb: usb@11201000 {
			compatible = "mediatek,mtu3";
			reg = <0 0x11201000 0 0x2e00>,
			      <0 0x11203e00 0 0x0100>,
			      <0 0x11200000 0 0x1000>;
			reg-names = "mac", "ippc", "xhci";
			interrupts = <GIC_SPI 16 IRQ_TYPE_LEVEL_LOW>;
			clocks = <&topckgen CLK_TOP_SSUSB_TOP_CK_EN>,
				 <&infracfg CLK_IFR_SSUSB_REF>,
				 <&infracfg CLK_IFR_SSUSB_SYS>,
				 <&infracfg CLK_IFR_ICUSB>,
				 <&infracfg CLK_IFR_SSUSB_XHCI>;
			clock-names = "sys_ck", "ref_ck", "mcu_ck",
				      "dma_ck", "xhci_ck";
			#address-cells = <2>;
			#size-cells = <2>;
			ranges;
			status = "disabled";

			usb_host0: xhci@11200000 {
				compatible = "mediatek,mtk-xhci";
				reg = <0 0x11200000 0 0x1000>;
				reg-names = "mac";
				interrupts = <GIC_SPI 67 IRQ_TYPE_LEVEL_LOW>;
				status = "okay";
			};
		};

		afe: audio-controller@11220000 {
			compatible = "mediatek,mt8168-afe-pcm";
			reg = <0 0x11220000 0 0x1000>,
			      <0 0x11221000 0 0xA000>;
			interrupts = <GIC_SPI 97 IRQ_TYPE_LEVEL_LOW>;
			power-domains = <&scpsys MT8168_POWER_DOMAIN_AUDIO>;
			clocks = <&topckgen CLK_TOP_AUDIO_SEL>,
				 <&topckgen CLK_TOP_AUD_I2S0_M>,
				 <&topckgen CLK_TOP_AUD_I2S1_M>,
				 <&topckgen CLK_TOP_AUD_I2S2_M>,
				 <&topckgen CLK_TOP_AUD_I2S3_M>,
				 <&topckgen CLK_TOP_AUD_TDMOUT_M>,
				 <&topckgen CLK_TOP_AUD_TDMOUT_B>,
				 <&topckgen CLK_TOP_AUD_TDMIN_M>,
				 <&topckgen CLK_TOP_AUD_TDMIN_B>,
				 <&topckgen CLK_TOP_AUD_SPDIF_M>,
				 <&topckgen CLK_TOP_AUD_SPDIF_SEL>,
				 <&topckgen CLK_TOP_AUD_ENGEN1_SEL>,
				 <&topckgen CLK_TOP_AUD_ENGEN2_SEL>,
				 <&topckgen CLK_TOP_AUD_1_SEL>,
				 <&topckgen CLK_TOP_AUD_2_SEL>,
				 <&topckgen CLK_TOP_APLL_I2S0_SEL>,
				 <&topckgen CLK_TOP_APLL_I2S1_SEL>,
				 <&topckgen CLK_TOP_APLL_I2S2_SEL>,
				 <&topckgen CLK_TOP_APLL_I2S3_SEL>,
				 <&topckgen CLK_TOP_APLL_TDMOUT_SEL>,
				 <&topckgen CLK_TOP_APLL_TDMIN_SEL>,
				 <&topckgen CLK_TOP_APLL_SPDIF_SEL>,
				 <&topckgen CLK_TOP_SYSPLL3_D4>,
				 <&topckgen CLK_TOP_CLK26M>,
				 <&topckgen CLK_TOP_SYSPLL1_D4>,
				 <&topckgen CLK_TOP_SYSPLL4_D2>,
				 <&topckgen CLK_TOP_AUD_INTBUS_SEL>;
			clock-names = "top_audio_sel",
				      "audio_i2s0_m",
				      "audio_i2s1_m",
				      "audio_i2s2_m",
				      "audio_i2s3_m",
				      "audio_tdmout_m",
				      "audio_tdmout_b",
				      "audio_tdmin_m",
				      "audio_tdmin_b",
				      "audio_spdif_m",
				      "spdif_in",
				      "engen1",
				      "engen2",
				      "aud1",
				      "aud2",
				      "i2s0_m_sel",
				      "i2s1_m_sel",
				      "i2s2_m_sel",
				      "i2s3_m_sel",
				      "tdmout_m_sel",
				      "tdmin_m_sel",
				      "spdif_b_sel",
				      "syspll3_d4",
				      "top_clk26m_clk",
				      "syspll1_d4",
				      "syspll4_d2",
				      "audio_intbus_sel";
			assigned-clocks = <&topckgen CLK_TOP_AUD_1_SEL>,
					  <&topckgen CLK_TOP_AUD_2_SEL>,
					  <&topckgen CLK_TOP_AUD_ENGEN1_SEL>,
					  <&topckgen CLK_TOP_AUD_ENGEN2_SEL>;
			assigned-clock-parents = <&topckgen CLK_TOP_APLL1>,
						 <&topckgen CLK_TOP_APLL2>,
						 <&topckgen CLK_TOP_APLL1_D8>,
						 <&topckgen CLK_TOP_APLL2_D8>;
			mediatek,topckgen-regmap = <&topckgen>;
			status = "disable";
		};

		mtk-btcvsd-snd@18050000 {
			compatible = "mediatek,mtk-btcvsd-snd";
			reg=<0 0x18050000 0 0x1000>, /*PKV_PHYSICAL_BASE*/
			    <0 0x18080000 0 0x10000>; /*SRAM_BANK2*/
			interrupts = <GIC_SPI 210 IRQ_TYPE_LEVEL_LOW>;
			mediatek,infracfg = <&infracfg>;
			mediatek,offset =<0xf00 0x800 0x140 0x144 0x148>;
			/*INFRA MISC, conn_bt_cvsd_mask*/
			/*cvsd_mcu_read, write, packet_indicator*/
		};

		mmc0: mmc@11230000 {
			compatible = "mediatek,mt8168-mmc";
			reg = <0 0x11230000 0 0x1000>,
			      <0 0x11cd0000 0 0x1000>;
			interrupts = <GIC_SPI 23 IRQ_TYPE_LEVEL_LOW>;
			clocks = <&topckgen CLK_TOP_MSDC50_0_SEL>,
				 <&infracfg CLK_IFR_MSDC0_HCLK>,
				 <&infracfg CLK_IFR_MSDC0_SRC>;
			clock-names = "source", "hclk", "source_cg";
			status = "disabled";
		};

		mmc1: mmc@11240000 {
			compatible = "mediatek,mt8168-mmc";
			reg = <0 0x11240000 0 0x1000>,
			      <0 0x11c90000 0 0x1000>;
			interrupts = <GIC_SPI 24 IRQ_TYPE_LEVEL_LOW>;
			clocks = <&topckgen CLK_TOP_MSDC30_1_SEL>,
				 <&infracfg CLK_IFR_MSDC1_HCLK>,
				 <&infracfg CLK_IFR_MSDC1_SRC>;
			clock-names = "source", "hclk", "source_cg";
			status = "disabled";
		};

		mmc2: mmc@11250000 {
			compatible = "mediatek,mt8168-sdio";
			reg = <0 0x11250000 0 0x1000>,
			      <0 0x11c60000 0 0x1000>;
			interrupts = <GIC_SPI 68 IRQ_TYPE_LEVEL_LOW>;
			clocks = <&topckgen CLK_TOP_MSDC50_2_SEL>,
				 <&infracfg CLK_IFR_MSDC2_HCLK>,
				 <&infracfg CLK_IFR_MSDC2_SRC>,
				 <&infracfg CLK_IFR_MSDC2_BK>,
				 <&infracfg CLK_IFR_AP_MSDC0>;
			clock-names = "source", "hclk", "source_cg",
				      "bus_clk", "ext_clk";
			status = "disabled";
		};

		ethernet: ethernet@112a0000 {
			compatible = "mediatek,mt8168-ethernet";
			reg = <0 0x112a0000 0 0x1000>,
			      <0 0x10001c00 0 0x100>;
			interrupts = <GIC_SPI 25 IRQ_TYPE_LEVEL_HIGH>;
			eth-gpios = <&pio 21 0>;
			clocks = <&topckgen CLK_TOP_ETH_SEL>,
				 <&infracfg CLK_IFR_NIC_AXI>,
				 <&infracfg CLK_IFR_NIC_SLV_AXI>;
			clock-names = "core", "reg", "trans";
			/*eth-regulator-supply = <&mt6392_vmch_reg>;*/
			mac-address = [00 00 00 00 00 00];
			status = "disabled";
		};

		adsp_pcm: adsp_pcm {
			compatible = "mediatek,mt8168-adsp-pcm";
			status = "disable";
		};

		mipi_tx0: mipi_tx0@0x11c00000 {
			compatible = "mediatek,mipi_tx0",
				     "mediatek,mt8183-mipi-tx";
			reg = <0 0x11c00000 0 0x800>;
			clocks = <&clk26m>;
			#clock-cells = <0>;
			#phy-cells = <0>;
			clock-output-names = "mipi_tx0_pll";
		};

		mipi_rx_ana_csi0a: mipi_rx_ana_csi0a@11c10000 {
			compatible = "mediatek,mipi_rx_ana_csi0a", "syscon";
			reg = <0 0x11c10000 0 0x1000>;
			#clock-cells = <1>;
		};

		mipi_rx_ana_csi0b: mipi_rx_ana_csi0b@11c11000 {
			compatible = "mediatek,mipi_rx_ana_csi0b", "syscon";
			reg = <0 0x11c11000 0 0x1000>;
			#clock-cells = <1>;
		};

		mipi_rx_ana_csi1a: mipi_rx_ana_csi1a@11c12000 {
			compatible = "mediatek,mipi_rx_ana_csi1a", "syscon";
			reg = <0 0x11c12000 0 0x1000>;
			#clock-cells = <1>;
		};

		mipi_rx_ana_csi1b: mipi_rx_ana_csi1b@11c13000 {
			compatible = "mediatek,mipi_rx_ana_csi1b", "syscon";
			reg = <0 0x11c13000 0 0x1000>;
			#clock-cells = <1>;
		};

		efuse: efuse@11c50000 {
			compatible = "mediatek,mt8168-efuse",
				     "mediatek,efuse";
			reg = <0 0x11c50000 0 0x1000>;
			#address-cells = <1>;
			#size-cells = <1>;
			svs_calibration: calib@580 {
				reg = <0x580 0x20>;
			};
			power_leakage: leakage@cd4 {
				reg = <0xcd4 0x4>;
			};
		};

		u3phy0: usb-phy@11cc0000 {
			compatible = "mediatek,generic-tphy-v2";
			clocks = <&topckgen CLK_TOP_USB20_48M_EN>;
			clock-names = "u3phya_ref";
			#address-cells = <2>;
			#size-cells = <2>;
			ranges;
			status = "disabled";

			u2port0: usb-phy@11cc0000 {
				reg = <0 0x11cc0000 0 0x400>;
				clocks = <&topckgen CLK_TOP_SSUSB_PHY_CK_EN>;
				clock-names = "ref";
				#phy-cells = <1>;
				status = "okay";
			};

			u2port1: usb-phy@11cc1000 {
				reg = <0 0x11cc1000 0 0x400>;
				clocks = <&topckgen CLK_TOP_SSUSB_PHY_CK_EN>;
				clock-names = "ref";
				#phy-cells = <1>;
				status = "okay";
			};
		};

		mfgcfg: syscon@13000000 {
			compatible = "mediatek,mt8168-mfgcfg", "syscon";
			reg = <0 0x13000000 0 0x1000>;
			#clock-cells = <1>;
		};

		mali@13040000 {
			compatible = "mediatek,mali",
				     "arm,mali-midgard",
				     "arm,mali-bifrost";
			reg = <0 0x13040000 0 0x4000>;
			interrupts =
				<GIC_SPI 201 IRQ_TYPE_LEVEL_LOW>,
				<GIC_SPI 202 IRQ_TYPE_LEVEL_LOW>,
				<GIC_SPI 203 IRQ_TYPE_LEVEL_LOW>,
				<GIC_SPI 204 IRQ_TYPE_LEVEL_LOW>;
			interrupt-names =
				"GPU",
				"MMU",
				"JOB",
				"EVENT";
		};

		mmsys: syscon@14000000 {
			compatible = "mediatek,mt8168-mmsys", "syscon";
			reg = <0 0x14000000 0 0x1000>;
			#clock-cells = <1>;
		};

		mmsys_config: mmsys_config@14000000 {
			compatible = "mediatek,mmsys_config", "syscon";
			reg = <0 0x14000000 0 0x1000>;
			interrupts = <GIC_SPI 171 IRQ_TYPE_LEVEL_LOW>;
			#clock-cells = <1>;
			clocks = <&mmsys CLK_MM_MM_CAM_MDP>,
				 <&mmsys CLK_MM_IMG_IMG_DL_RELAY>,
				 <&mmsys CLK_MM_IMG_IMG_DL_ASYNC_TOP>;
			clock-names = "CAM_MDP", "IMG_DL_RELAY",
				      "IMG_DL_ASYNC_TOP";
		};
		display_components: dispsys@14000000 {
			compatible = "mediatek,mt8168-display";
			reg = <0 0x14000000 0 0x1000>;
			power-domains = <&scpsys MT8168_POWER_DOMAIN_DISP>;
			mediatek,gce = <&gce_mbox>;
			mboxes = <&gce_mbox 0 0 1>,
				 <&gce_mbox 1 0 1>,
				 <&gce_mbox 2 0 1>;
			gce-event-names = "stream_done_0",
					  "stream_done_1",
					  "stream_done_2";
			gce-events = <&gce_mbox 130>,
				     <&gce_mbox 131>,
				     <&gce_mbox 132>;
		};

		disp_mutex0: disp_mutex@14001000 {
			compatible = "mediatek,disp_mutex0",
				     "mediatek,mt8168-disp-mutex";
			reg = <0 0x14001000 0 0x1000>;
			interrupts = <GIC_SPI 154 IRQ_TYPE_LEVEL_LOW>;
			gce-event-names = "stream_done_0",
					  "stream_done_1",
					  "stream_done_2";
			gce-events = <&gce_mbox 130>,
				     <&gce_mbox 131>,
				     <&gce_mbox 132>;
		};

		smi_common: smi@14002000 {
			compatible = "mediatek,mt8168-smi-common", "syscon";
			reg = <0 0x14002000 0 0x1000>;
			clocks = <&mmsys CLK_MM_MM_SMI_COMMON>,
				 <&mmsys CLK_MM_MM_SMI_COMMON>,
				 <&mmsys CLK_MM_MM_SMI_COMM0>,
				 <&mmsys CLK_MM_MM_SMI_COMM1>;
			clock-names = "apb", "smi", "gals0", "gals1";
			mediatek,mmsys = <&mmsys_config>;
		};

		larb0: larb@14003000 {
			compatible = "mediatek,mt8168-smi-larb",
				     "mediatek,mt8183-smi-larb";
			reg = <0 0x14003000 0 0x1000>;
			mediatek,smi = <&smi_common>;
			mediatek,larb-id = <0>;
			clocks = <&mmsys CLK_MM_MM_SMI_LARB0>,
				 <&mmsys CLK_MM_MM_SMI_LARB0>;
			clock-names = "apb", "smi";
		};

		mdp_rdma0: mdp_rdma0@14004000 {
			compatible = "mediatek,mdp_rdma0",
				     "mediatek,mt8168-mdp-rdma",
				     "mediatek,mt8168-mdp";
			reg = <0 0x14004000 0 0x1000>;
			mediatek,mdpid = <0>;
			interrupts = <GIC_SPI 155 IRQ_TYPE_LEVEL_LOW>;
			power-domains = <&scpsys MT8168_POWER_DOMAIN_DISP>;
			clocks = <&mmsys CLK_MM_MM_MDP_RDMA0>;
			clock-names = "MDP_RDMA0";
			iommus = <&iommu M4U_PORT_MDP_RDMA0>;
			mediatek,larb = <&larb0>;
			mediatek,vcu = <&mdp_vcu>;
			mediatek,mailbox-gce = <&gce_mbox>;
			mboxes = <&gce_mbox 15 0 1>;
			gce-event-names = "rdma0_sof",
					  "rdma1_sof",
					  "rsz0_sof",
					  "rsz1_sof",
					  "tdshp0_sof",
					  "wrot0_sof",
					  "wrot1_sof",
					  "rdma0_done",
					  "rdma1_done",
					  "wrot0_done",
					  "wrot1_done",
					  "wrot0_sram_ready",
					  "wrot1_sram_ready";
			gce-events = <&gce_mbox 0>,
				     <&gce_mbox 21>,
				     <&gce_mbox 2>,
				     <&gce_mbox 3>,
				     <&gce_mbox 6>,
				     <&gce_mbox 5>,
				     <&gce_mbox 4>,
				     <&gce_mbox 23>,
				     <&gce_mbox 42>,
				     <&gce_mbox 27>,
				     <&gce_mbox 28>,
				     <&gce_mbox 710>,
				     <&gce_mbox 711>;
		};

		mdp_vcu: vcu@1 {
			compatible = "mediatek,mt8168-vcu";
			mediatek,vcuid = <1>;
			mediatek,vcuname = "vpu1";
			iommus = <&iommu M4U_PORT_HW_VDEC_MC_EXT>;
		};

		mdp_ccorr: mdp_ccorr0@14005000 {
			compatible = "mediatek,mdp_ccorr0",
				     "mediatek,mt8168-mdp-ccorr";
			reg = <0 0x14005000 0 0x1000>;
			interrupts = <GIC_SPI 170 IRQ_TYPE_LEVEL_LOW>;
			power-domains = <&scpsys MT8168_POWER_DOMAIN_DISP>;
			clocks = <&mmsys CLK_MM_MM_MDP_CCORR0>;
			clock-names = "MDP_CCORR";
		};

		mdp_rsz0: mdp_rsz0@14006000 {
			compatible = "mediatek,mdp_rsz0",
				     "mediatek,mt8168-mdp-rsz";
			reg = <0 0x14006000 0 0x1000>;
			interrupts = <GIC_SPI 156 IRQ_TYPE_LEVEL_LOW>;
			power-domains = <&scpsys MT8168_POWER_DOMAIN_DISP>;
			clocks = <&mmsys CLK_MM_MM_MDP_RSZ0>;
			clock-names = "MDP_RSZ0";
		};

		mdp_rsz1: mdp_rsz1@14007000 {
			compatible = "mediatek,mdp_rsz1",
				     "mediatek,mt8168-mdp-rsz";
			reg = <0 0x14007000 0 0x1000>;
			interrupts = <GIC_SPI 157 IRQ_TYPE_LEVEL_LOW>;
			power-domains = <&scpsys MT8168_POWER_DOMAIN_DISP>;
			clocks = <&mmsys CLK_MM_MM_MDP_RSZ1>;
			clock-names = "MDP_RSZ1";
		};

		mdp_wrot1: mdp_wrot1@14008000 {
			compatible = "mediatek,mdp_wrot1",
				     "mediatek,mt8168-mdp-wrot";
			reg = <0 0x14008000 0 0x1000>;
			interrupts = <GIC_SPI 159 IRQ_TYPE_LEVEL_LOW>;
			power-domains = <&scpsys MT8168_POWER_DOMAIN_DISP>;
			clocks = <&mmsys CLK_MM_MM_MDP_WDMA0>;
			clock-names = "MDP_WROT1";
			iommus = <&iommu M4U_PORT_MDP_WROT1>;
			mediatek,larb = <&larb0>;
		};

		mdp_wrot0: mdp_wrot0@14009000 {
			compatible = "mediatek,mdp_wrot0",
				     "mediatek,mt8168-mdp-wrot";
			reg = <0 0x14009000 0 0x1000>;
			interrupts = <GIC_SPI 160 IRQ_TYPE_LEVEL_LOW>;
			power-domains = <&scpsys MT8168_POWER_DOMAIN_DISP>;
			clocks = <&mmsys CLK_MM_MM_MDP_WROT0>;
			clock-names = "MDP_WROT0";
			iommus = <&iommu M4U_PORT_MDP_WROT0>;
			mediatek,larb = <&larb0>;
		};


		mdp_tdshp0: mdp_tdshp0@1400a000 {
			compatible = "mediatek,mdp_tdshp0",
				     "mediatek,mt8168-mdp-tdshp";
			reg = <0 0x1400a000 0 0x1000>;
			power-domains = <&scpsys MT8168_POWER_DOMAIN_DISP>;
			clocks = <&mmsys CLK_MM_MM_MDP_TDSHP0>;
			clock-names = "MDP_TDSHP";
		};

		disp_ovl0: ovl@1400b000 {
			compatible = "mediatek,disp_ovl0",
				     "mediatek,mt8168-disp-ovl";
			reg = <0 0x1400b000 0 0x1000>;
			interrupts = <GIC_SPI 161 IRQ_TYPE_LEVEL_LOW>;
			power-domains = <&scpsys MT8168_POWER_DOMAIN_DISP>;
			clocks = <&mmsys CLK_MM_MM_DISP_OVL0>;
			iommus = <&iommu M4U_PORT_DISP_OVL0>;
			mediatek,larb = <&larb0>;
			gce-subsys = <&gce_mbox 0x14000000 1>;
		};

		disp_ovl0_2l: ovl@1400c000 {
			compatible = "mediatek,disp_ovl0_2l",
				     "mediatek,mt8168-disp-ovl-2l";
			reg = <0 0x1400c000 0 0x1000>;
			interrupts = <GIC_SPI 173 IRQ_TYPE_LEVEL_LOW>;
			power-domains = <&scpsys MT8168_POWER_DOMAIN_DISP>;
			clocks = <&mmsys CLK_MM_MM_DISP_OVL0_21>;
			iommus = <&iommu M4U_PORT_DISP_OVL0_2L>;
			mediatek,larb = <&larb0>;
			gce-subsys = <&gce_mbox 0x14000000 1>;
		};

		disp_rdma0: rdma@1400d000 {
			compatible = "mediatek,disp_rdma0",
				     "mediatek,mt8168-disp-rdma";
			reg = <0 0x1400d000 0 0x1000>;
			interrupts = <GIC_SPI 162 IRQ_TYPE_LEVEL_LOW>;
			power-domains = <&scpsys MT8168_POWER_DOMAIN_DISP>;
			clocks = <&mmsys CLK_MM_MM_DISP_RDMA0>;
			iommus = <&iommu M4U_PORT_DISP_RDMA0>;
			mediatek,larb = <&larb0>;
			gce-subsys = <&gce_mbox 0x14000000 1>;
		};

		disp_wdma0: wdma@1400e000 {
			compatible = "mediatek,disp_wdma0",
				     "mediatek,mt8168-disp-wdma";
			reg = <0 0x1400e000 0 0x1000>;
			interrupts = <GIC_SPI 163 IRQ_TYPE_LEVEL_LOW>;
			power-domains = <&scpsys MT8168_POWER_DOMAIN_DISP>;
			clocks = <&mmsys CLK_MM_MM_DISP_WDMA0>;
			iommus = <&iommu M4U_PORT_DISP_WDMA0>;
			mediatek,larb = <&larb0>;
			gce-subsys = <&gce_mbox 0x14000000 1>;
		};

		disp_color0: color@1400f000 {
			compatible = "mediatek,disp_color0",
				     "mediatek,mt8168-disp-color";
			reg = <0 0x1400f000 0 0x1000>;
			interrupts = <GIC_SPI 164 IRQ_TYPE_LEVEL_LOW>;
			power-domains = <&scpsys MT8168_POWER_DOMAIN_DISP>;
			clocks = <&mmsys CLK_MM_MM_DISP_COLOR0>;
			gce-subsys = <&gce_mbox 0x14000000 1>;
		};

		disp_ccorr0: ccorr@14010000 {
			compatible = "mediatek,disp_ccorr0",
				     "mediatek,mt8168-disp-ccorr";
			reg = <0 0x14010000 0 0x1000>;
			interrupts = <GIC_SPI 165 IRQ_TYPE_LEVEL_LOW>;
			power-domains = <&scpsys MT8168_POWER_DOMAIN_DISP>;
			clocks = <&mmsys CLK_MM_MM_DISP_CCORR0>;
			gce-subsys = <&gce_mbox 0x14010000 2>;
		};

		disp_aal0: aal@14011000 {
			compatible = "mediatek,disp_aal0",
				     "mediatek,mt8168-disp-aal";
			reg = <0 0x14011000 0 0x1000>;
			interrupts = <GIC_SPI 166 IRQ_TYPE_LEVEL_LOW>;
			power-domains = <&scpsys MT8168_POWER_DOMAIN_DISP>;
			clocks = <&mmsys CLK_MM_MM_DISP_AAL0>;
			gce-subsys = <&gce_mbox 0x14010000 2>;
		};

		disp_gamma0: gamma@14012000 {
			compatible = "mediatek,disp_gamma0",
				     "mediatek,mt8168-disp-gamma";
			reg = <0 0x14012000 0 0x1000>;
			interrupts = <GIC_SPI 167 IRQ_TYPE_LEVEL_LOW>;
			power-domains = <&scpsys MT8168_POWER_DOMAIN_DISP>;
			clocks = <&mmsys CLK_MM_MM_DISP_GAMMA0>;
		};

		disp_dither0: dither@14013000 {
			compatible = "mediatek,disp_dither0",
				     "mediatek,mt8168-disp-dither";
			reg = <0 0x14013000 0 0x1000>;
			interrupts = <GIC_SPI 168 IRQ_TYPE_LEVEL_LOW>;
			power-domains = <&scpsys MT8168_POWER_DOMAIN_DISP>;
			clocks = <&mmsys CLK_MM_MM_DISP_DITHER0>;
			gce-subsys = <&gce_mbox 0x14010000 2>;
		};

		dsi0: dsi0@14014000 {
			compatible = "mediatek,dsi0", "mediatek,mt8183-dsi";
			reg = <0 0x14014000 0 0x1000>;
			interrupts = <GIC_SPI 169 IRQ_TYPE_LEVEL_LOW>;
			power-domains = <&scpsys MT8168_POWER_DOMAIN_DISP>;
			clocks = <&mmsys CLK_MM_MM_DSI0>,
				 <&mmsys CLK_MM_DSI0_DIG_DSI>,
				 <&mipi_tx0>;
			clock-names = "engine", "digital", "hs";
			phys = <&mipi_tx0>;
			phy-names = "dphy";
		};

		disp_rsz0: rsz@14015000 {
			compatible = "mediatek,disp_rsz0",
				     "mediatek,mt8168-disp-rsz";
			reg = <0 0x14015000 0 0x1000>;
			interrupts = <GIC_SPI 220 IRQ_TYPE_LEVEL_LOW>;
			power-domains = <&scpsys MT8168_POWER_DOMAIN_DISP>;
			clocks = <&mmsys CLK_MM_MM_DISP_RSZ0>;
			gce-subsys = <&gce_mbox 0x14010000 2>;
		};

		disp_rdma1: rdma@14016000 {
			compatible = "mediatek,disp_rdma1",
				     "mediatek,mt8168-disp-rdma";
			reg = <0 0x14016000 0 0x1000>;
			interrupts = <GIC_SPI 195 IRQ_TYPE_LEVEL_LOW>;
			power-domains = <&scpsys MT8168_POWER_DOMAIN_DISP>;
			clocks = <&mmsys CLK_MM_MM_DISP_RDMA1>;
			iommus = <&iommu M4U_PORT_DISP_RDMA1>;
			mediatek,larb = <&larb0>;
			gce-subsys = <&gce_mbox 0x14010000 2>;
		};

		mdp_rdma1: mdp_rdma1@14017000 {
			compatible = "mediatek,mdp_rdma1",
				     "mediatek,mt8168-mdp-rdma";
			reg = <0 0x14017000 0 0x1000>;
			interrupts = <GIC_SPI 196 IRQ_TYPE_LEVEL_LOW>;
			power-domains = <&scpsys MT8168_POWER_DOMAIN_DISP>;
			clocks = <&mmsys CLK_MM_MM_MDP_RDMA1>;
			clock-names = "MDP_RDMA1";
			iommus = <&iommu M4U_PORT_MDP_RDMA1>;
			mediatek,larb = <&larb0>;
		};

		dpi0@14018000 {
			compatible = "mediatek,dpi0";
			reg = <0 0x14018000 0 0x1000>;
			interrupts = <GIC_SPI 197 IRQ_TYPE_LEVEL_LOW>;
		};

		lvdstx@14019200 {
			compatible = "mediatek,lvdstx";
			reg = <0 0x14019200 0 0x100>;
		};

		lvdsana@11c00800 {
			compatible = "mediatek,lvdsana";
			reg = <0 0x11c00800 0 0x30>;
		};

		extd_drv: extd_drv@0 {
			compatible = "mediatek,extd_dev";
		};

		mtkfb: mtkfb@0 {
			compatible = "mediatek,mtkfb";
		};

		dispsys {
			compatible = "mediatek,dispsys";
			mediatek,larb = <&larb0>;
			iommus =
				<&iommu M4U_PORT_DISP_OVL0>,
				<&iommu M4U_PORT_DISP_OVL0_2L>,
				<&iommu M4U_PORT_DISP_RDMA0>,
				<&iommu M4U_PORT_DISP_WDMA0>,
				<&iommu M4U_PORT_DISP_RDMA1>;
			clocks =
				<&mmsys CLK_MM_MM_SMI_COMMON>,
				<&mmsys CLK_MM_MM_SMI_LARB0>,
				<&mmsys CLK_MM_MM_SMI_COMM0>,
				<&mmsys CLK_MM_MM_SMI_COMM1>,
				<&mmsys CLK_MM_MM_DISP_OVL0>,
				<&mmsys CLK_MM_MM_DISP_OVL0_21>,
				<&mmsys CLK_MM_MM_DISP_RDMA0>,
				<&mmsys CLK_MM_MM_DISP_RDMA1>,
				<&mmsys CLK_MM_MM_DISP_WDMA0>,
				<&mmsys CLK_MM_MM_DISP_COLOR0>,
				<&mmsys CLK_MM_MM_DISP_CCORR0>,
				<&mmsys CLK_MM_MM_DISP_AAL0>,
				<&mmsys CLK_MM_MM_DISP_GAMMA0>,
				<&mmsys CLK_MM_MM_DISP_DITHER0>,
				<&mmsys CLK_MM_MM_DSI0>,
				<&mmsys CLK_MM_DSI0_DIG_DSI>,
				<&mmsys CLK_MM_26M_HRTWT>,
				<&mmsys CLK_MM_MM_DISP_RSZ0>,
				<&mmsys CLK_MM_DPI0_DPI0>,
				<&mmsys CLK_MM_MM_DPI0>,
				<&mmsys CLK_MM_LVDSTX_PXL>,
				<&mmsys CLK_MM_LVDSTX_CTS>,
				<&topckgen CLK_TOP_LVDSTX_CLKDIG_EN>,
				<&topckgen CLK_TOP_VPLL_DPIX_EN>,
				<&topckgen CLK_TOP_UNIVPLL2_D4>,
				<&topckgen CLK_TOP_DISP_PWM_SEL>,
				<&infracfg CLK_IFR_DISP_PWM>,
				<&apmixedsys CLK_APMIXED_LVDSPLL>,
				<&topckgen CLK_TOP_DPI0_SEL>,
				<&topckgen CLK_TOP_LVDSPLL_D2>,
				<&topckgen CLK_TOP_LVDSPLL_D4>,
				<&topckgen CLK_TOP_LVDSPLL_D8>,
				<&topckgen CLK_TOP_LVDSPLL_D16>,
				<&clk26m>;

			clock-names =
				"MMSYS_SMI_COMMON",
				"MMSYS_SMI_LARB0",
				"MMSYS_GALS_COMM0",
				"MMSYS_GALS_COMM1",
				"MMSYS_DISP_OVL0",
				"MMSYS_DISP_OVL0_2L",
				"MMSYS_DISP_RDMA0",
				"MMSYS_DISP_RDMA1",
				"MMSYS_DISP_WDMA0",
				"MMSYS_DISP_COLOR0",
				"MMSYS_DISP_CCORR0",
				"MMSYS_DISP_AAL0",
				"MMSYS_DISP_GAMMA0",
				"MMSYS_DISP_DITHER0",
				"MMSYS_DSI0_MM_CK",
				"MMSYS_DSI0_IF_CK",
				"MMSYS_26M",
				"MMSYS_DISP_RSZ0",
				"MMSYS_DPI0_DPI0",
				"MMSYS_DPI0",
				"MMSYS_LVDSTX_PXL",
				"MMSYS_LVDSTX_CTS",
				"TOP_LVDSTX_CLKDIG_EN",
				"TOP_VPLL_DPIX_EN",
				"TOP_UNIVPLL2_D4",
				"TOP_MUX_DISP_PWM",
				"DISP_PWM",
				"APMIXED_LVDSPLL",
				"DPI0_SEL",
				"TOP_LVDSPLL_D2",
				"TOP_LVDSPLL_D4",
				"TOP_LVDSPLL_D8",
				"TOP_LVDSPLL_D16",
				"TOP_26M";

			power-domains = <&scpsys MT8168_POWER_DOMAIN_DISP>;
		};

		dsi_te: dsi_te {
			compatible = "mediatek, DSI_TE-eint";
			status = "disabled";
		};

		camsys: syscon@15000000 {
			compatible = "mediatek,mt8168-imgsys", "syscon";
			reg = <0 0x15000000 0 0x1000>;
			#clock-cells = <1>;
		};

		ispsys: ispsys@15000000 {
			compatible = "mediatek,mt8168-ispsys";
			reg = <0x0 0x15004000 0x0 0x9000>,
				<0x0 0x1500d000 0x0 0x1000>,
				<0x0 0x15000000 0x0 0x52000>,
				<0x0 0x10215000 0x0 0x3000>,
				<0x0 0x10211000 0x0 0x1000>,
				<0x0 0x15040000 0x0 0x8000>,
				<0x0 0x15050000 0x0 0x2000>;

			interrupts = <GIC_SPI 179 IRQ_TYPE_LEVEL_LOW>,
				<GIC_SPI 180 IRQ_TYPE_LEVEL_LOW>,
				<GIC_SPI 181 IRQ_TYPE_LEVEL_LOW>,
				<GIC_SPI 186 IRQ_TYPE_LEVEL_LOW>,
				<GIC_SPI 187 IRQ_TYPE_LEVEL_LOW>;

			power-domains = <&scpsys MT8168_POWER_DOMAIN_CAM>;

			mediatek,larb = <&larb2>;

			iommus =	<&iommu M4U_PORT_CAM_IMGO>,
					<&iommu M4U_PORT_CAM_RRZO>,
					<&iommu M4U_PORT_CAM_AAO>,
					<&iommu M4U_PORT_CAM_ESFKO>,
					<&iommu M4U_PORT_CAM_CAM_SV0>,
					<&iommu M4U_PORT_CAM_LSCI>,
					<&iommu M4U_PORT_CAM_LSCI_D>,
					<&iommu M4U_PORT_CAM_BPCI>,
					<&iommu M4U_PORT_CAM_BPCI_D>,
					<&iommu M4U_PORT_CAM_IMGI>,
					<&iommu M4U_PORT_CAM_IMG2O>;

			clocks =	<&mmsys CLK_MM_MM_SMI_COMMON>,
					<&mmsys CLK_MM_MM_SMI_COMM0>,
					<&mmsys CLK_MM_MM_SMI_COMM1>,
					<&mmsys CLK_MM_MM_SMI_IMG>,
					<&camsys CLK_CAM_LARB2>,
					<&camsys CLK_CAM>,
					<&camsys CLK_CAMTG>,
					<&camsys CLK_CAM_SENIF>,
					<&camsys CLK_CAMSV0>,
					<&camsys CLK_CAMSV1>;

			clock-names =	"MMSYS_SMI_COMMON",
					"MMSYS_SMI_COMM0",
					"MMSYS_SMI_COMM1",
					"MMSYS_SMI_IMG",
					"CAMSYS_LARB2",
					"CAMSYS_CAM",
					"CAMSYS_CAMTG",
					"CAMSYS_SENIF",
					"CAMSYS_CAMSV0",
					"CAMSYS_CAMSV1";
		};


		larb2: larb@15001000 {
			compatible = "mediatek,mt8168-smi-larb",
				     "mediatek,mt8183-smi-larb";
			reg = <0 0x15001000 0 0x1000>;
			mediatek,smi = <&smi_common>;
			mediatek,larb-id = <2>;
			clocks = <&mmsys CLK_MM_MM_SMI_IMG>,
				 <&camsys CLK_CAM_LARB2>;
			clock-names = "apb", "smi";
		};

		fdvt: fdvt@1500b000 {
			compatible = "mediatek,fdvt";
			reg = <0 0x1500b000 0 0x1000>;
			interrupts = <GIC_SPI 182 IRQ_TYPE_LEVEL_LOW>;
		};

		wpe: wpe@1500c000 {
			compatible = "mediatek,mt8168-wpe",
				     "mediatek,wpe";
			reg = <0 0x1500c000 0 0x1000>;
			interrupts = <GIC_SPI 188 IRQ_TYPE_LEVEL_LOW>;
			clocks = <&camsys CLK_CAM_WPE>;
			clock-names = "wpe";
			power-domains = <&scpsys MT8168_POWER_DOMAIN_CAM>;
			iommus = <&iommu M4U_PORT_CAM_WPE0_I>,
				 <&iommu M4U_PORT_CAM_WPE1_I>,
				 <&iommu M4U_PORT_CAM_WPE_O>;
			mediatek,larb = <&larb2>;
		};

		kd_camera_hw1: kd_camera_hw1@15040000 {
			compatible = "mediatek,camera_hw";
			reg = <0 0x15040000 0 0x1000>;
			/* SENINF_ADDR */
			/* Camera Common Clock Framework (CCF) */
			clocks = <&topckgen CLK_TOP_CAMTG_SEL>,
				 <&topckgen CLK_TOP_CAMTG1_SEL>,
				 <&topckgen CLK_TOP_USB20_192M_D8>,
				 <&topckgen CLK_TOP_CLK26M>,
				 <&topckgen CLK_TOP_USB20_192M_D4>,
				 <&topckgen CLK_TOP_UNIVPLL2_D8>,
				 <&topckgen CLK_TOP_USB20_192M_D16>,
				 <&topckgen CLK_TOP_UNIVPLL2_D32>,
				 <&topckgen CLK_TOP_USB20_192M_D32>,
				 <&camsys CLK_CAM_SENIF>,
				 <&mipi_rx_ana_csi0a CLK_MIPI0A_CSR_CSI_EN_0A>,
				 <&mipi_rx_ana_csi0b CLK_MIPI0B_CSR_CSI_EN_0B>,
				 <&mipi_rx_ana_csi1a CLK_MIPI1A_CSR_CSI_EN_1A>,
				 <&mipi_rx_ana_csi1b CLK_MIPI1B_CSR_CSI_EN_1B>,
				 <&topckgen CLK_TOP_CAMTM_SEL>,
				 <&topckgen CLK_TOP_SENIF_SEL>,
				 <&topckgen CLK_TOP_UNIVPLL2_D2>;
			clock-names =
				"CLK_TOP_CAMTG_SEL",
				"CLK_TOP_CAMTG1_SEL",
				"CLK_MCLK_24M",
				"CLK_MCLK_26M",
				"CLK_MCLK_48M",
				"CLK_MCLK_52M",
				"CLK_MCLK_12M",
				"CLK_MCLK_13M",
				"CLK_MCLK_6M",
				"CLK_CAM_SENIF_CG",
				"CLK_MIPI_ANA_0A_CG",
				"CLK_MIPI_ANA_0B_CG",
				"CLK_MIPI_ANA_1A_CG",
				"CLK_MIPI_ANA_1B_CG",
				"CLK_TOP_CAMTM_SEL_CG",
				"CLK_TOP_SENIF_SEL_CG",
				"CLK_TOP_SELIF_SRC_208";
		};

		vcu: vcu@16000000 {
			compatible = "mediatek-vcu",
				     "mediatek,mt8168-vcu";
			mediatek,vcuid = <0>;
			mediatek,vcuname = "vcu";
			reg = <0 0x16000000 0 0x40000>,	    /* VDEC_BASE */
				 <0 0x17020000 0 0x10000>,  /* VENC_BASE */
				 <0 0x19002000 0 0x1000>;   /* VENC_LT */
			iommus = <&iommu M4U_PORT_HW_VDEC_MC_EXT>;
			mediatek,mailbox-gce = <&gce_mbox>;
			mboxes =
				<&gce_mbox 13 0 4>,
				<&gce_mbox 14 0 4>;

			gce-event-names =
				"vdec_pic_start",
				"vdec_decode_done",
				"vdec_pause",
				"vdec_dec_error",
				"vdec_mc_busy_overflow_timeout",
				"vdec_all_dram_req_done",
				"vdec_ini_fetch_rdy",
				"vdec_process_flag",
				"vdec_search_start_code_done",
				"vdec_ref_reorder_done",
				"vdec_wp_tble_done",
				"vdec_count_sram_clr_done",
				"venc_eof",
				"venc_cmdq_pause_done",
				"venc_mb_done",
				"venc_128B_cnt_done";

			gce-events =
				<&gce_mbox 352>,
				<&gce_mbox 353>,
				<&gce_mbox 354>,
				<&gce_mbox 355>,
				<&gce_mbox 356>,
				<&gce_mbox 357>,
				<&gce_mbox 358>,
				<&gce_mbox 359>,
				<&gce_mbox 360>,
				<&gce_mbox 361>,
				<&gce_mbox 362>,
				<&gce_mbox 363>,
				<&gce_mbox 364>,
				<&gce_mbox 365>,
				<&gce_mbox 366>,
				<&gce_mbox 367>;
		};

		vdecsys: syscon@16000000 {
			compatible = "mediatek,mt8168-vdecsys", "syscon";
			reg = <0 0x16000000 0 0x1000>;
			#clock-cells = <1>;
		};

		vdec_gcon: vdec_gcon@16000000 {
			compatible = "mediatek,vdec_gcon", "syscon";
			reg = <0 0x16000000 0 0x1000>,		/* VDEC_SYS */
			      <0 0x16025000 0 0x1000>;		/* VDEC_MISC */
			mediatek,larb = <&larb3>;
			interrupts = <GIC_SPI 177 IRQ_TYPE_LEVEL_LOW>;
			iommus =
				<&iommu M4U_PORT_HW_VDEC_MC_EXT>,
				<&iommu M4U_PORT_HW_VDEC_PP_EXT>,
				<&iommu M4U_PORT_HW_VDEC_PRED_RD_EXT>,
				<&iommu M4U_PORT_HW_VDEC_PRED_WR_EXT>,
				<&iommu M4U_PORT_HW_VDEC_PPWRAP_EXT>,
				<&iommu M4U_PORT_HW_VDEC_TILE_EXT>,
				<&iommu M4U_PORT_HW_VDEC_VLD_EXT>,
				<&iommu M4U_PORT_HW_VDEC_VLD2_EXT>,
				<&iommu M4U_PORT_HW_VDEC_AVC_MV_EXT>,
				<&iommu M4U_PORT_HW_VDEC_RG_CTRL_DMA_EXT>;
			mediatek,vcu = <&vcu>;
			power-domains = <&scpsys MT8168_POWER_DOMAIN_VDEC>;
			clocks =
				<&vdecsys CLK_VDEC_VDEC>,
				<&vdecsys CLK_VDEC_LARB1>;
			clock-names =
				"hf_hvdec_ck",
				"hf_flarb1_ck";
			#clock-cells = <1>;
		};

		larb3: larb@16010000 {
			compatible = "mediatek,mt8168-smi-larb",
				     "mediatek,mt8183-smi-larb";
			reg = <0 0x16010000 0 0x1000>;
			mediatek,smi = <&smi_common>;
			mediatek,larb-id = <3>;
			clocks = <&vdecsys CLK_VDEC_LARB1>,
				 <&vdecsys CLK_VDEC_LARB1>;
			clock-names = "apb", "smi";
		};

		venc_gcon: venc_gcon@17000000 {
			compatible = "mediatek,venc_gcon";
			reg = <0 0x17000000 0 0x1000>,
				<0 0x17020000 0 0x1000>;
			mediatek,larb = <&larb1>;
			interrupts = <GIC_SPI 174 IRQ_TYPE_LEVEL_LOW>;
			iommus =
				<&iommu M4U_PORT_VENC_RCPU>,
				<&iommu M4U_PORT_VENC_REC>,
				<&iommu M4U_PORT_VENC_BSDMA>,
				<&iommu M4U_PORT_VENC_SV_COMV>,
				<&iommu M4U_PORT_VENC_RD_COMV>,
				<&iommu M4U_PORT_VENC_CUR_LUMA>,
				<&iommu M4U_PORT_VENC_CUR_CHROMA>,
				<&iommu M4U_PORT_VENC_REF_LUMA>,
				<&iommu M4U_PORT_VENC_REF_CHROMA>;
			mediatek,vcu = <&vcu>;
			power-domains = <&scpsys MT8168_POWER_DOMAIN_VENC>;
			clocks =
				<&vencsys CLK_VENC>,
				<&vencsys CLK_VENC_JPGENC>;
			clock-names =
				"MT_CG_VENC",
				"MT_CG_VENC_JPGENC";
			#clock-cells = <1>;
		};

		vencsys: syscon@17000000 {
			compatible = "mediatek,mt8168-vencsys", "syscon";
			reg = <0 0x17000000 0 0x1000>;
			#clock-cells = <1>;
		};

		larb1: larb@17010000 {
			compatible = "mediatek,mt8168-smi-larb",
				     "mediatek,mt8183-smi-larb";
			reg = <0 0x17010000 0 0x1000>;
			mediatek,smi = <&smi_common>;
			mediatek,larb-id = <1>;
			clocks = <&vencsys CLK_VENC>, <&vencsys CLK_VENC>;
			clock-names = "apb", "smi";
		};

		venc@17020000 {
			compatible = "mediatek,venc";
			reg = <0 0x17020000 0 0x2000>;
		};

		jpgenc@17030000 {
			compatible = "mediatek,mt8168-jpgenc",
				     "mediatek,venc_jpg";
			reg = <0 0x17030000 0 0x1000>;
			interrupts = <GIC_SPI 176 IRQ_TYPE_LEVEL_LOW>;
			iommus =
				<&iommu M4U_PORT_JPGENC_Y_RDMA>,
				<&iommu M4U_PORT_JPGENC_C_RDMA>,
				<&iommu M4U_PORT_JPGENC_BSDMA>;
			power-domains = <&scpsys MT8168_POWER_DOMAIN_VENC>;
		};

		wifi: wifi@18000000 {
			compatible = "mediatek,wifi";
			reg = <0 0x18000000 0 0x100000>;
			interrupts = <GIC_SPI 212 IRQ_TYPE_LEVEL_LOW>;
		};

/* sensor part */
		gsensor@0 {
			compatible = "mediatek,gsensor";
		};
		gyro:gyroscope@0 {
			compatible = "mediatek,gyroscope";
		};
		msensor@0 {
			compatible = "mediatek,msensor";
		};

/*  bmi160_acc start */
cust_accel_bmi160:cust_accel@0 {
		compatible				= "mediatek,cust_acc_bmi160";
	};
/*  bmi160_acc end */
/*  icm426 start */
cust_accel_icm426:cust_accel@8 {
		compatible				= "mediatek,cust_acc_icm426";
};
cust_gyro_icm426:cust_gyro@2{
	compatible			= "mediatek,cust_gyro_icm426";
};		
/*  icm426  end */
cust_gyro_bmi160:cust_gyro@1{
		compatible			= "mediatek,cust_gyro_bmi160";
	};
/*  bmi160_gyro end */
/*  mmc3630x start */
cust_mag_mmc3630x:cust_mag@4{
	compatible = "mediatek,cust_mag_mmc3630x";
};
/*  mmc3630x end */
/* sensor end */

		consys: consys@18002000 {
			compatible = "mediatek,mt8168-consys";
			#address-cells = <2>;
			#size-cells = <2>;
				/*CONN_MCU_CONFIG_BASE */
			reg = <0 0x18002000 0 0x1000>,
				/*TOP_RGU_BASE */
				<0 0x10007000 0 0x0100>,
				/*INFRACFG_AO_BASE */
				<0 0x10001000 0 0x1000>,
				/*SPM_BASE */
				<0 0x10006000 0 0x1000>,
				/*CONN_HIF_ON_BASE */
				<0 0x18007000 0 0x1000>,
				/*CONN_TOP_MISC_OFF_BASE */
				<0 0x180b1000 0 0x1000>,
				/*CONN_MCU_CFG_ON_BASE */
				<0 0x180a3000 0 0x1000>,
				/*CONN_MCU_CIRQ_BASE */
				<0 0x180a5000 0 0x800>,
				/*CONN_TOP_MISC_ON_BASE */
				<0 0x180c1000 0 0x1000>,
				/*CONN_HIF_PDMA_BASE */
				<0 0x18004000 0 0x1000>;
				/*BGF_EINT */
			interrupts = <GIC_SPI 211 IRQ_TYPE_LEVEL_LOW>,
				/*WDT_EINT */
				   <GIC_SPI 213 IRQ_TYPE_LEVEL_LOW>,
				/*conn2ap_sw_irq*/
				   <GIC_SPI 214 IRQ_TYPE_EDGE_RISING>;
			power-domains = <&scpsys MT8168_POWER_DOMAIN_CONN>;
			resets = <&toprgu MT8168_TOPRGU_CONN_MCU_RST>;
			reset-names = "connsys";
			status = "disabled";
		};

		vpu: vpu@19000000 {
			compatible = "mediatek,mt8168-vpu";
			reg = <0 0x19020000 0 0x1000>;
			mediatek,vpucore = <&vpu_core0>;
			mediatek,larb = <&larb3>;
			iommus = <&iommu M4U_PORT_APU_READ>,
				<&iommu M4U_PORT_APU_WRITE>;
		};

		apu: apu@19020000 {
			compatible = "mediatek,mt8168-apu", "syscon";
			reg = <0 0x19020000 0 0x1000>;
			#clock-cells = <1>;
		};

		mtk_edmc: edmc@19030000 {
			compatible = "mtk,edmc";
			reg = <0 0x19000000 0 0x1000>,
			      <0 0x19030000 0 0x1000>;
			interrupts = <GIC_SPI 209 IRQ_TYPE_LEVEL_LOW>;
		};

		vpu_core0: vpu_core@19100000 {
			compatible = "mediatek,mt8168-vpu-core";
			reg = <0 0x19100000 0 0x94000>;
			interrupts = <GIC_SPI 199 IRQ_TYPE_LEVEL_LOW>;
			power-domains = <&scpsys MT8168_POWER_DOMAIN_APU>;
			clocks = <&topckgen CLK_TOP_APU_SEL>,
				 <&topckgen CLK_TOP_APU_IF_SEL>,
				 <&topckgen CLK_TOP_CLK26M>,
				 <&topckgen CLK_TOP_UNIVPLL_D2>,
				 <&topckgen CLK_TOP_APUPLL>,
				 <&topckgen CLK_TOP_MMPLL>,
				 <&topckgen CLK_TOP_SYSPLL_D3>,
				 <&topckgen CLK_TOP_UNIVPLL1_D2>,
				 <&topckgen CLK_TOP_SYSPLL1_D2>,
				 <&topckgen CLK_TOP_SYSPLL1_D4>,
				 <&infracfg CLK_IFR_APU_AXI>,
				 <&mmsys CLK_MM_MM_SMI_CAM>,
				 <&apu CLK_APU_IPU_CK>,
				 <&apu CLK_APU_AXI>,
				 <&apu CLK_APU_JTAG>,
				 <&apu CLK_APU_IF_CK>,
				 <&apu CLK_APU_EDMA>,
				 <&apu CLK_APU_AHB>;
			clock-names = "apu_sel",
				      "apu_if_sel",
				      "clk26m_ck",
				      "univpll_d2",
				      "apupll_ck",
				      "mmpll_ck",
				      "syspll_d3",
				      "univpll1_d2",
				      "syspll1_d2",
				      "syspll1_d4",
				      "ifr_apu_axi",
				      "smi_cam",
				      "apu_ipu_ck",
				      "apu_axi",
				      "apu_jtag",
				      "apu_if_ck",
				      "apu_edma",
				      "apu_ahb";
		};

		adsp: adsp@1d062000 {
			compatible = "mediatek,audio_dsp";
			reg = <0 0x1d062000 0 0x01000>, /* DSPCFG reg */
			      <0 0x1e000000 0 0x60000>, /* DTCM 384KB */
			      <0 0x1e100000 0 0x18000>; /* ITCM 96KB */
				/* config reserve-memory size for adsp */
			memory-region = <&adsp_reserved>;
				/* config shared-dram size from reserve-mem */
			size_shared_dram_from_tail = <0xc00000>;
				/* ADSP IPI NOTIFY IRQ */
			interrupts = <GIC_SPI 208 IRQ_TYPE_LEVEL_HIGH>,
				/* dsp_wdt IRQ */
				<GIC_SPI 53 IRQ_TYPE_LEVEL_LOW>;
			power-domains = <&scpsys MT8168_POWER_DOMAIN_DSP>;
			clocks =
				<&topckgen CLK_TOP_DSP_SEL>,
				<&topckgen CLK_TOP_CLK26M>,
				<&topckgen CLK_TOP_SYS_26M_D2>,
				<&topckgen CLK_TOP_DSPPLL>,
				<&topckgen CLK_TOP_DSPPLL_D2>,
				<&topckgen CLK_TOP_DSPPLL_D4>,
				<&topckgen CLK_TOP_DSPPLL_D8>,
				<&topckgen CLK_TOP_DSP_26M>,
				<&topckgen CLK_TOP_DSP_32K>,
				<&infracfg CLK_IFR_DSP_UART>;
			clock-names =
				"CLK_DSP_SEL",
				"CLK26M_CK",
				"AD_SYS_26M_D2",
				"DSPPLL_CK",
				"DSPPLL_D2",
				"DSPPLL_D4",
				"DSPPLL_D8",
				"PDN_DSP_26M",
				"PDN_DSP_32K",
				"IFR_DSP_UART";
		};

		gpufreq {
			compatible = "mediatek,mt8168-gpufreq";
			clocks =
				<&topckgen CLK_TOP_MFG_SEL>,
				<&apmixedsys CLK_APMIXED_MFGPLL>,
				<&topckgen CLK_TOP_MFGPLL>,
				<&topckgen CLK_TOP_UNIVPLL_D3>,
				<&mfgcfg CLK_MFG_BG3D>,
				<&mfgcfg CLK_MFG_MBIST_DIAG>;
			clock-names =
				"clk_mux",
				"clk_pll_src",
				"clk_main_parent",
				"clk_sub_parent",
				"subsys_mfg_cg",
				"subsys_mfg_mbist_diag";
			power-domains = <&scpsys MT8168_POWER_DOMAIN_MFG>;
		};

		ice: ice_debug {
			compatible = "mediatek,mt8168-ice_debug",
				     "mediatek,mt2701-ice_debug";
			clocks = <&infracfg CLK_IFR_DEBUGSYS>;
			clock-names = "ice_dbg";
		};

		pseudo-m4u {
			compatible = "mediatek,mtk-pseudo-m4u";
			iommus = <&iommu M4U_PORT_DISP_FAKE0>;
		};

		led6: led@6 {
			compatible = "mediatek,lcd-backlight";
			led_mode = <5>;
			data = <1>;
			pwm_config = <0 0 0 0 0>;
		};

		mtee {
			compatible = "mediatek,mtee";
			clocks = <&infracfg CLK_IFR_GCPU>,
				<&topckgen CLK_TOP_GCPU_SEL>;
			clock-names = "GCPU", "GCPU_B";
		};

		mmdvfs_pmqos: mmdvfs_pmqos {
			compatible = "mediatek,mmdvfs_pmqos";
			mm_step0 = <457 2 6 0x1193b1>;
			mm_step1 = <320 2 6 0xc4ec4>;
			mm_step2 = <200 2 6 0x7b13b>;
			vopp_steps = <0 1 2>;
			disp_freq = "mm_step0", "mm_step1", "mm_step2";
			mdp_freq = "mm_step0", "mm_step1", "mm_step2";
			cam_freq = "mm_step0","mm_step1","mm_step2";
			vdec_freq = "mm_step0","mm_step1","mm_step2";
			venc_freq = "mm_step0","mm_step1","mm_step2";
			clocks = <&topckgen CLK_TOP_MM_SEL>,		/* 0 */
				 <&topckgen CLK_TOP_MMPLL>,		/* 1 */
				 <&topckgen CLK_TOP_SYSPLL1_D4>,	/* 2 */
				 <&apmixedsys CLK_APMIXED_MMPLL>;	/* 3 */
			clock-names = "mmdvfs_clk_mm_sel_ck",		/* 0 */
				      "mmdvfs_clk_mmpll_ck",		/* 1 */
				      "mmdvfs_clk_syspll1_d4_ck",	/* 2 */
				      "mmdvfs_clk_mmpll";		/* 3 */
		};

		accdet: accdet@ {
			compatible = "mediatek,pmic-accdet";
		};

		touch: touch@ {
			compatible = "mediatek,mt8168-touch";
			status = "okay";
		};

		spower: spower {
			compatible = "mediatek,mt8168-spower";
			nvmem-cells = <&svs_calibration>,
				      <&power_leakage>;
			nvmem-cell-names = "spower_calibration",
					   "spower_leakage";
		};
	};
};

#include "bat_setting/tb8168_battery_prop_ext.dtsi"
#include "mt8168-clkao.dtsi"
